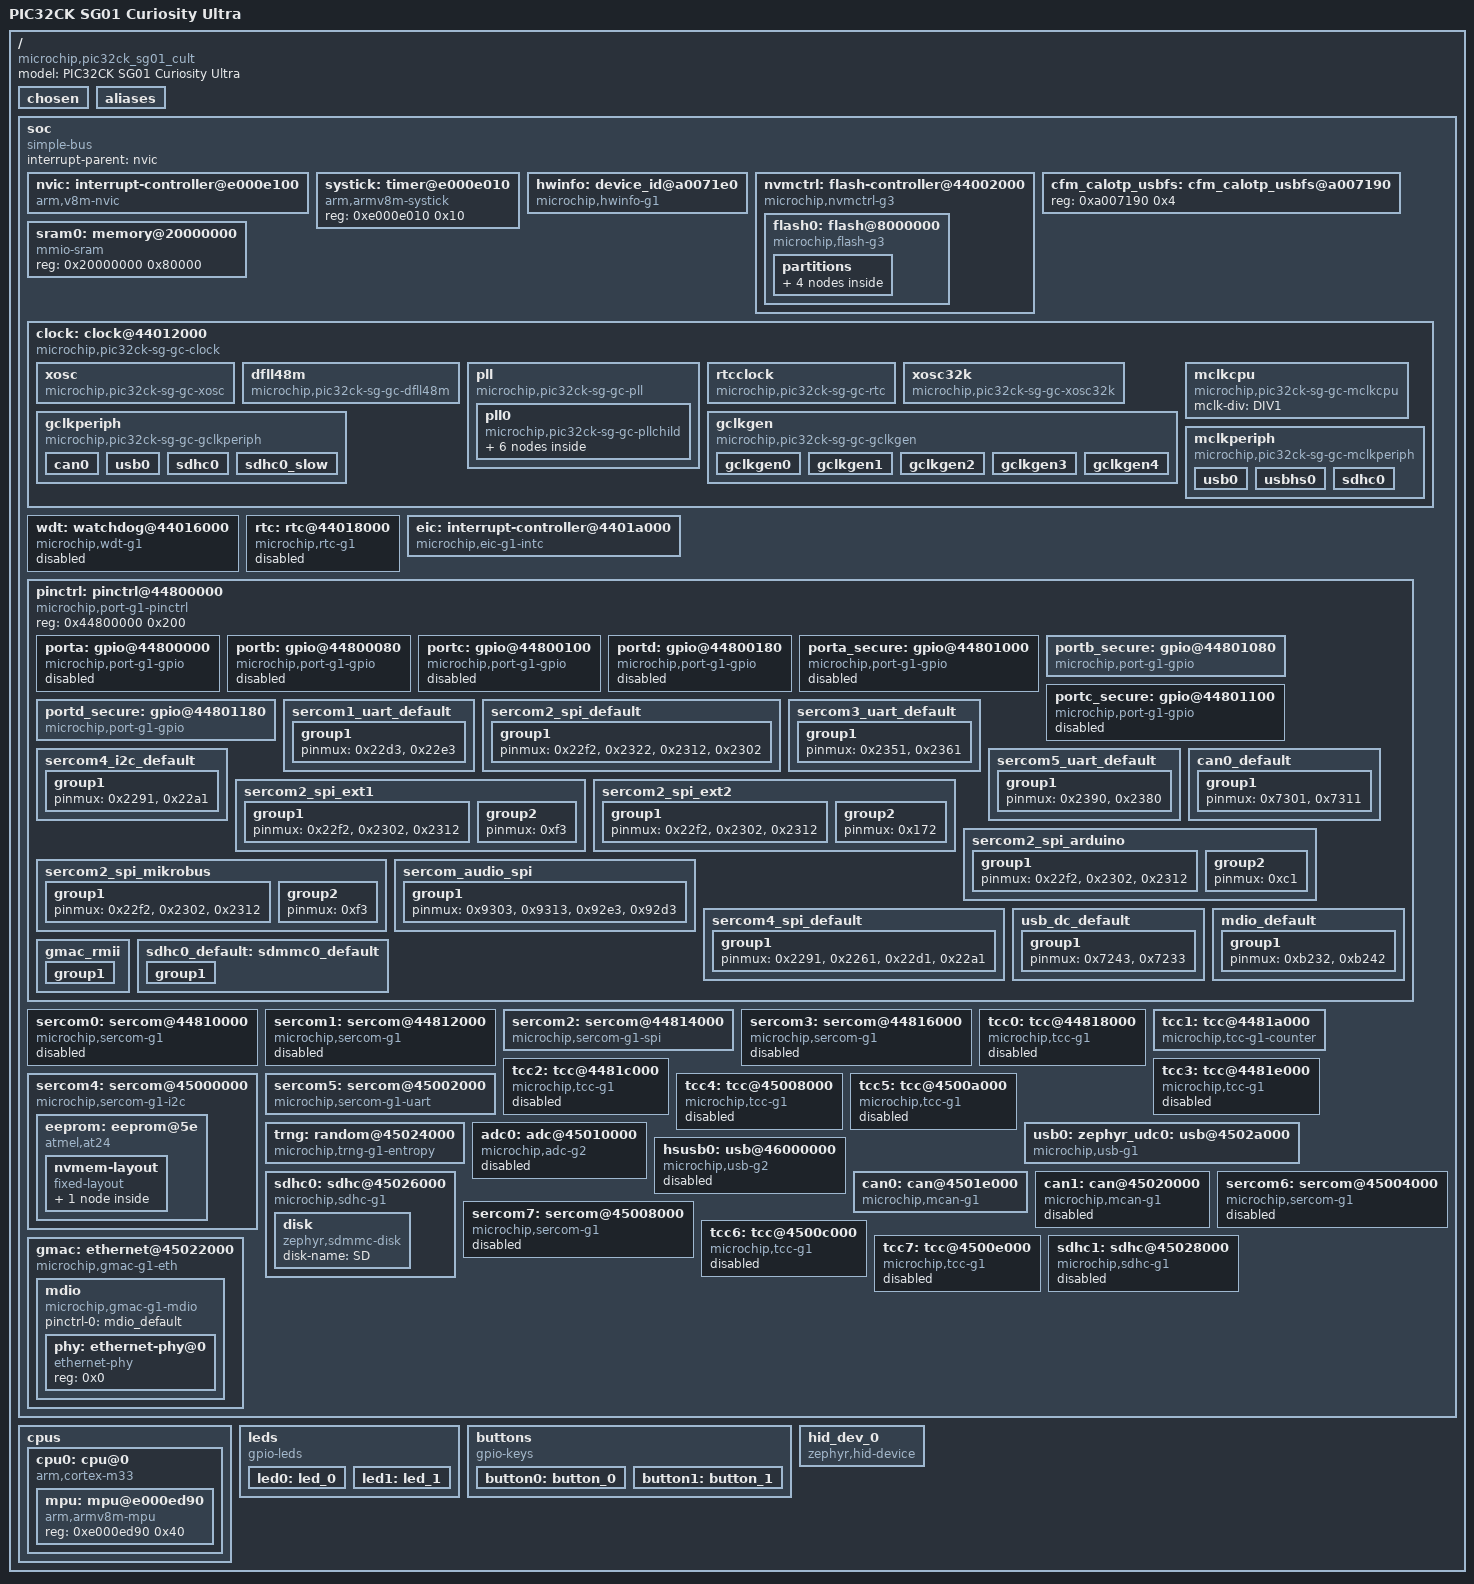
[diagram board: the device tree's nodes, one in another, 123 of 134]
/dts-v1/;

/* node '/' defined in zephyr\dts\common\skeleton.dtsi:9 */
/ {
	#address-cells = < 0x1 >;                   /* in zephyr\dts\common\skeleton.dtsi:10 */
	#size-cells = < 0x1 >;                      /* in zephyr\dts\common\skeleton.dtsi:11 */
	model = "PIC32CK SG01 Curiosity Ultra";     /* in zephyr\boards\microchip\pic32c\pic32ck_sg01_cult\pic32ck_sg01_cult.dts:14 */
	compatible = "microchip,pic32ck_sg01_cult"; /* in zephyr\boards\microchip\pic32c\pic32ck_sg01_cult\pic32ck_sg01_cult.dts:15 */

	/* node '/chosen' defined in zephyr\dts\common\skeleton.dtsi:13 */
	chosen {
		zephyr,sram = &sram0;                     /* in zephyr\boards\microchip\pic32c\pic32ck_sg01_cult\pic32ck_sg01_cult.dts:18 */
		zephyr,flash = &flash0;                   /* in zephyr\boards\microchip\pic32c\pic32ck_sg01_cult\pic32ck_sg01_cult.dts:19 */
		zephyr,flash-controller = &nvmctrl;       /* in zephyr\boards\microchip\pic32c\pic32ck_sg01_cult\pic32ck_sg01_cult.dts:20 */
		zephyr,code-partition = &slot0_partition; /* in zephyr\boards\microchip\pic32c\pic32ck_sg01_cult\pic32ck_sg01_cult.dts:21 */
		zephyr,console = &sercom5;                /* in zephyr\boards\microchip\pic32c\pic32ck_sg01_cult\pic32ck_sg01_cult.dts:22 */
		zephyr,shell-uart = &sercom5;             /* in zephyr\boards\microchip\pic32c\pic32ck_sg01_cult\pic32ck_sg01_cult.dts:23 */
		zephyr,canbus = &can0;                    /* in zephyr\boards\microchip\pic32c\pic32ck_sg01_cult\pic32ck_sg01_cult.dts:24 */
		zephyr,entropy = &trng;                   /* in zephyr\boards\microchip\pic32c\pic32ck_sg01_cult\pic32ck_sg01_cult.dts:25 */
		zephyr,sdhc = &sdhc0;                     /* in zephyr\boards\microchip\pic32c\pic32ck_sg01_cult\pic32ck_sg01_cult.dts:26 */
	};

	/* node '/aliases' defined in zephyr\dts\common\skeleton.dtsi:15 */
	aliases {
		watchdog0 = &wdt; /* in zephyr\dts\arm\microchip\pic32c\pic32ck_sg_gc\common\pic32ck_sg_gc.dtsi:13 */
		led0 = &led0;     /* in zephyr\boards\microchip\pic32c\pic32ck_sg01_cult\pic32ck_sg01_cult.dts:30 */
		led1 = &led1;     /* in zephyr\boards\microchip\pic32c\pic32ck_sg01_cult\pic32ck_sg01_cult.dts:31 */
		sw0 = &button0;   /* in zephyr\boards\microchip\pic32c\pic32ck_sg01_cult\pic32ck_sg01_cult.dts:32 */
		sw1 = &button1;   /* in zephyr\boards\microchip\pic32c\pic32ck_sg01_cult\pic32ck_sg01_cult.dts:33 */
		spi0 = &sercom2;  /* in zephyr\boards\microchip\pic32c\pic32ck_sg01_cult\pic32ck_sg01_cult.dts:34 */
		i2c0 = &sercom4;  /* in zephyr\boards\microchip\pic32c\pic32ck_sg01_cult\pic32ck_sg01_cult.dts:35 */
		sdhc0 = &sdhc0;   /* in zephyr\boards\microchip\pic32c\pic32ck_sg01_cult\pic32ck_sg01_cult.dts:36 */
	};

	/* node '/soc' defined in zephyr\dts\arm\armv8-m.dtsi:6 */
	soc {
		#address-cells = < 0x1 >;     /* in zephyr\dts\arm\armv8-m.dtsi:7 */
		#size-cells = < 0x1 >;        /* in zephyr\dts\arm\armv8-m.dtsi:8 */
		compatible = "simple-bus";    /* in zephyr\dts\arm\armv8-m.dtsi:9 */
		interrupt-parent = < &nvic >; /* in zephyr\dts\arm\armv8-m.dtsi:10 */
		ranges;                       /* in zephyr\dts\arm\armv8-m.dtsi:11 */

		/* node '/soc/interrupt-controller@e000e100' defined in zephyr\dts\arm\armv8-m.dtsi:13 */
		nvic: interrupt-controller@e000e100 {
			arm,num-irq-priority-bits = < 0x3 >; /* in zephyr\dts\arm\microchip\pic32c\pic32ck_sg_gc\common\pic32ck_sg_gc.dtsi:452 */
			#address-cells = < 0x1 >;            /* in zephyr\dts\arm\armv8-m.dtsi:14 */
			compatible = "arm,v8m-nvic";         /* in zephyr\dts\arm\armv8-m.dtsi:15 */
			reg = < 0xe000e100 0xc00 >;          /* in zephyr\dts\arm\armv8-m.dtsi:16 */
			interrupt-controller;                /* in zephyr\dts\arm\armv8-m.dtsi:17 */
			#interrupt-cells = < 0x2 >;          /* in zephyr\dts\arm\armv8-m.dtsi:18 */
			phandle = < 0x1 >;                   /* in zephyr\dts\arm\armv8-m.dtsi:10 */
		};

		/* node '/soc/timer@e000e010' defined in zephyr\dts\arm\armv8-m.dtsi:21 */
		systick: timer@e000e010 {
			compatible = "arm,armv8m-systick"; /* in zephyr\dts\arm\armv8-m.dtsi:22 */
			reg = < 0xe000e010 0x10 >;         /* in zephyr\dts\arm\armv8-m.dtsi:23 */
		};

		/* node '/soc/device_id@a0071e0' defined in zephyr\dts\arm\microchip\pic32c\pic32ck_sg_gc\common\pic32ck_sg_gc.dtsi:35 */
		hwinfo: device_id@a0071e0 {
			compatible = "microchip,hwinfo-g1"; /* in zephyr\dts\arm\microchip\pic32c\pic32ck_sg_gc\common\pic32ck_sg_gc.dtsi:36 */
			reg = < 0xa0071e0 0x4 >,
			      < 0xa0071e4 0x4 >,
			      < 0xa0071e8 0x4 >,
			      < 0xa0071ec 0x4 >;            /* in zephyr\dts\arm\microchip\pic32c\pic32ck_sg_gc\common\pic32ck_sg_gc.dtsi:37 */
		};

		/* node '/soc/flash-controller@44002000' defined in zephyr\dts\arm\microchip\pic32c\pic32ck_sg_gc\common\pic32ck_sg_gc.dtsi:43 */
		nvmctrl: flash-controller@44002000 {
			compatible = "microchip,nvmctrl-g3"; /* in zephyr\dts\arm\microchip\pic32c\pic32ck_sg_gc\common\pic32ck_sg_gc.dtsi:44 */
			reg = < 0x44002000 0x60 >,
			      < 0x44004000 0x7c >;           /* in zephyr\dts\arm\microchip\pic32c\pic32ck_sg_gc\common\pic32ck_sg_gc.dtsi:45 */
			reg-names = "fcr",
			            "fcw";                   /* in zephyr\dts\arm\microchip\pic32c\pic32ck_sg_gc\common\pic32ck_sg_gc.dtsi:46 */
			clock-parent = < &clock >;           /* in zephyr\dts\arm\microchip\pic32c\pic32ck_sg_gc\common\pic32ck_sg_gc.dtsi:47 */
			clocks = < &mclkperiph 0x24017f02 >,
			         < &mclkperiph 0x2410bf13 >,
			         < &mclkperiph 0x24013f01 >,
			         < &mclkperiph 0x24107f12 >; /* in zephyr\dts\arm\microchip\pic32c\pic32ck_sg_gc\common\pic32ck_sg_gc.dtsi:48 */
			clock-names = "mclk-fcw-ahb",
			              "mclk-fcw-apb",
			              "mclk-fcr-ahb",
			              "mclk-fcr-apb";        /* in zephyr\dts\arm\microchip\pic32c\pic32ck_sg_gc\common\pic32ck_sg_gc.dtsi:52 */
			interrupts = < 0x0 0x0 >,
			             < 0x1 0x0 >,
			             < 0x2 0x0 >;            /* in zephyr\dts\arm\microchip\pic32c\pic32ck_sg_gc\common\pic32ck_sg_gc.dtsi:54 */
			interrupt-names = "eccerr",
			                  "crcerr",
			                  "fcw";             /* in zephyr\dts\arm\microchip\pic32c\pic32ck_sg_gc\common\pic32ck_sg_gc.dtsi:55 */
			#address-cells = < 0x1 >;            /* in zephyr\dts\arm\microchip\pic32c\pic32ck_sg_gc\common\pic32ck_sg_gc.dtsi:56 */
			#size-cells = < 0x1 >;               /* in zephyr\dts\arm\microchip\pic32c\pic32ck_sg_gc\common\pic32ck_sg_gc.dtsi:57 */
			ranges;                              /* in zephyr\dts\arm\microchip\pic32c\pic32ck_sg_gc\common\pic32ck_sg_gc.dtsi:58 */

			/* node '/soc/flash-controller@44002000/flash@8000000' defined in zephyr\dts\arm\microchip\pic32c\pic32ck_sg_gc\common\pic32ck_sg_gc.dtsi:60 */
			flash0: flash@8000000 {
				compatible = "microchip,flash-g3",
				             "soc-nv-flash";                    /* in zephyr\dts\arm\microchip\pic32c\pic32ck_sg_gc\common\pic32ck_sg_gc.dtsi:61 */
				write-block-size = < 0x8 >;                     /* in zephyr\dts\arm\microchip\pic32c\pic32ck_sg_gc\common\pic32ck_sg_gc.dtsi:62 */
				write-block-size-quad-dw = < 0x20 >;            /* in zephyr\dts\arm\microchip\pic32c\pic32ck_sg_gc\common\pic32ck_sg_gc.dtsi:63 */
				write-block-size-row = < 0x400 >;               /* in zephyr\dts\arm\microchip\pic32c\pic32ck_sg_gc\common\pic32ck_sg_gc.dtsi:64 */
				erase-block-size = < 0x1000 >;                  /* in zephyr\dts\arm\microchip\pic32c\pic32ck_sg_gc\common\pic32ck_sg_gc.dtsi:65 */
				unimplemented-region = < 0x8020000 0xbffffff >; /* in zephyr\dts\arm\microchip\pic32c\pic32ck_sg_gc\common\pic32ck_sg_gc.dtsi:66 */
				reg = < 0x8000000 0x4200000 >;                  /* in zephyr\dts\arm\microchip\pic32c\pic32ck_sg_gc\common\pic32ck_2051_sg_gc.dtsi:13 */
				#address-cells = < 0x1 >;                       /* in zephyr\dts\arm\microchip\pic32c\pic32ck_sg_gc\common\pic32ck_2051_sg_gc.dtsi:15 */
				#size-cells = < 0x1 >;                          /* in zephyr\dts\arm\microchip\pic32c\pic32ck_sg_gc\common\pic32ck_2051_sg_gc.dtsi:16 */
				ranges = < 0x0 0x8000000 0x4200000 >;           /* in zephyr\dts\arm\microchip\pic32c\pic32ck_sg_gc\common\pic32ck_2051_sg_gc.dtsi:17 */

				/* node '/soc/flash-controller@44002000/flash@8000000/partitions' defined in zephyr\boards\microchip\pic32c\pic32ck_sg01_cult\pic32ck_sg01_cult.dts:71 */
				partitions {
					#address-cells = < 0x1 >; /* in zephyr\boards\microchip\pic32c\pic32ck_sg01_cult\pic32ck_sg01_cult.dts:72 */
					#size-cells = < 0x1 >;    /* in zephyr\boards\microchip\pic32c\pic32ck_sg01_cult\pic32ck_sg01_cult.dts:73 */
					ranges;                   /* in zephyr\boards\microchip\pic32c\pic32ck_sg01_cult\pic32ck_sg01_cult.dts:74 */

					/* node '/soc/flash-controller@44002000/flash@8000000/partitions/partition@0' defined in zephyr\boards\microchip\pic32c\pic32ck_sg01_cult\pic32ck_sg01_cult.dts:88 */
					boot_partition: partition@0 {
						compatible = "zephyr,mapped-partition"; /* in zephyr\boards\microchip\pic32c\pic32ck_sg01_cult\pic32ck_sg01_cult.dts:89 */
						label = "mcuboot";                      /* in zephyr\boards\microchip\pic32c\pic32ck_sg01_cult\pic32ck_sg01_cult.dts:90 */
						reg = < 0x0 0x20000 >;                  /* in zephyr\boards\microchip\pic32c\pic32ck_sg01_cult\pic32ck_sg01_cult.dts:91 */
					};

					/* node '/soc/flash-controller@44002000/flash@8000000/partitions/partition@4000000' defined in zephyr\boards\microchip\pic32c\pic32ck_sg01_cult\pic32ck_sg01_cult.dts:95 */
					slot0_partition: partition@4000000 {
						compatible = "zephyr,mapped-partition"; /* in zephyr\boards\microchip\pic32c\pic32ck_sg01_cult\pic32ck_sg01_cult.dts:96 */
						label = "image-0";                      /* in zephyr\boards\microchip\pic32c\pic32ck_sg01_cult\pic32ck_sg01_cult.dts:97 */
						reg = < 0x4000000 0xfc000 >;            /* in zephyr\boards\microchip\pic32c\pic32ck_sg01_cult\pic32ck_sg01_cult.dts:98 */
					};

					/* node '/soc/flash-controller@44002000/flash@8000000/partitions/partition@40fc000' defined in zephyr\boards\microchip\pic32c\pic32ck_sg01_cult\pic32ck_sg01_cult.dts:102 */
					slot1_partition: partition@40fc000 {
						compatible = "zephyr,mapped-partition"; /* in zephyr\boards\microchip\pic32c\pic32ck_sg01_cult\pic32ck_sg01_cult.dts:103 */
						label = "image-1";                      /* in zephyr\boards\microchip\pic32c\pic32ck_sg01_cult\pic32ck_sg01_cult.dts:104 */
						reg = < 0x40fc000 0xfc000 >;            /* in zephyr\boards\microchip\pic32c\pic32ck_sg01_cult\pic32ck_sg01_cult.dts:105 */
					};

					/* node '/soc/flash-controller@44002000/flash@8000000/partitions/partition@41f8000' defined in zephyr\boards\microchip\pic32c\pic32ck_sg01_cult\pic32ck_sg01_cult.dts:109 */
					storage_partition: partition@41f8000 {
						compatible = "zephyr,mapped-partition"; /* in zephyr\boards\microchip\pic32c\pic32ck_sg01_cult\pic32ck_sg01_cult.dts:110 */
						label = "storage";                      /* in zephyr\boards\microchip\pic32c\pic32ck_sg01_cult\pic32ck_sg01_cult.dts:111 */
						reg = < 0x41f8000 0x8000 >;             /* in zephyr\boards\microchip\pic32c\pic32ck_sg01_cult\pic32ck_sg01_cult.dts:112 */
					};
				};
			};
		};

		/* node '/soc/cfm_calotp_usbfs@a007190' defined in zephyr\dts\arm\microchip\pic32c\pic32ck_sg_gc\common\pic32ck_sg_gc.dtsi:71 */
		cfm_calotp_usbfs: cfm_calotp_usbfs@a007190 {
			reg = < 0xa007190 0x4 >; /* in zephyr\dts\arm\microchip\pic32c\pic32ck_sg_gc\common\pic32ck_sg_gc.dtsi:72 */
			phandle = < 0x9 >;       /* in zephyr\dts\arm\microchip\pic32c\pic32ck_sg_gc\common\pic32ck_sg_gc.dtsi:410 */
		};

		/* node '/soc/memory@20000000' defined in zephyr\dts\arm\microchip\pic32c\pic32ck_sg_gc\common\pic32ck_sg_gc.dtsi:75 */
		sram0: memory@20000000 {
			compatible = "mmio-sram";     /* in zephyr\dts\arm\microchip\pic32c\pic32ck_sg_gc\common\pic32ck_sg_gc.dtsi:76 */
			reg = < 0x20000000 0x80000 >; /* in zephyr\dts\arm\microchip\pic32c\pic32ck_sg_gc\common\pic32ck_2051_sg_gc.dtsi:23 */
		};

		/* node '/soc/clock@44012000' defined in zephyr\dts\arm\microchip\pic32c\pic32ck_sg_gc\common\pic32ck_sg_gc.dtsi:79 */
		clock: clock@44012000 {
			reg = < 0x44012000 0x2000 >,
			      < 0x4400c000 0x2000 >,
			      < 0x4400e000 0x2000 >,
			      < 0x44010000 0x2000 >,
			      < 0x44008000 0x2000 >;                  /* in zephyr\dts\arm\microchip\pic32c\pic32ck_sg_gc\common\pic32ck_sg_gc.dtsi:81 */
			reg-names = "mclk",
			            "oscctrl",
			            "osc32kctrl",
			            "gclk",
			            "supc";                           /* in zephyr\dts\arm\microchip\pic32c\pic32ck_sg_gc\common\pic32ck_sg_gc.dtsi:83 */
			interrupts = < 0x5 0x0 >,
			             < 0x5 0x0 >,
			             < 0x5 0x0 >,
			             < 0x6 0x0 >,
			             < 0x6 0x0 >,
			             < 0x6 0x0 >,
			             < 0x6 0x0 >,
			             < 0x6 0x0 >,
			             < 0x6 0x0 >,
			             < 0x7 0x0 >,
			             < 0x8 0x0 >,
			             < 0x8 0x0 >,
			             < 0x9 0x0 >;                     /* in zephyr\dts\arm\microchip\pic32c\pic32ck_sg_gc\common\pic32ck_sg_gc.dtsi:84 */
			interrupt-names = "xosc-fail",
			                  "xosc-crdy",
			                  "clk-fail",
			                  "dfll-rdy",
			                  "dfll-lock",
			                  "dfll-ovf",
			                  "dfll-unf",
			                  "dfll-rcs",
			                  "dfll-fail",
			                  "pll0-ckr",
			                  "xosc32k-rdy",
			                  "xosc32k-fail",
			                  "ckrdy";                    /* in zephyr\dts\arm\microchip\pic32c\pic32ck_sg_gc\common\pic32ck_sg_gc.dtsi:87 */
			compatible = "microchip,pic32ck-sg-gc-clock"; /* in zephyr\boards\microchip\pic32c\pic32ck_sg01_cult\pic32ck_sg01_cult.dts:122 */
			phandle = < 0x2 >;                            /* in zephyr\dts\arm\microchip\pic32c\pic32ck_sg_gc\common\pic32ck_sg_gc.dtsi:47 */

			/* node '/soc/clock@44012000/xosc' defined in zephyr\dts\arm\microchip\pic32c\pic32ck_sg_gc\common\pic32ck_sg_gc.dtsi:92 */
			xosc: xosc {
				compatible = "microchip,pic32ck-sg-gc-xosc";                 /* in zephyr\boards\microchip\pic32c\pic32ck_sg01_cult\pic32ck_sg01_cult.dts:125 */
				xosc-enable = < 0x1 >;                                       /* in zephyr\boards\microchip\pic32c\pic32ck_sg01_cult\pic32ck_sg01_cult.dts:126 */
				xosc-xtal-en = < 0x1 >;                                      /* in zephyr\boards\microchip\pic32c\pic32ck_sg01_cult\pic32ck_sg01_cult.dts:127 */
				xosc-auto-gain-control-loop-en = < 0x0 >;                    /* in zephyr\boards\microchip\pic32c\pic32ck_sg01_cult\pic32ck_sg01_cult.dts:128 */
				xosc-clock-switch-back-en = < 0x0 >;                         /* in zephyr\boards\microchip\pic32c\pic32ck_sg01_cult\pic32ck_sg01_cult.dts:129 */
				xosc-frequency = < 0xb71b00 >;                               /* in zephyr\boards\microchip\pic32c\pic32ck_sg01_cult\pic32ck_sg01_cult.dts:130 */
				xosc-on-demand-en = < 0x0 >;                                 /* in zephyr\boards\microchip\pic32c\pic32ck_sg01_cult\pic32ck_sg01_cult.dts:131 */
				xosc-startup-time = < 0x7a120 >;                             /* in zephyr\boards\microchip\pic32c\pic32ck_sg01_cult\pic32ck_sg01_cult.dts:132 */
				xosc-clock-failure-detection-en = < 0x0 >;                   /* in zephyr\boards\microchip\pic32c\pic32ck_sg01_cult\pic32ck_sg01_cult.dts:133 */
				xosc-safe-clock-frequency = < 0x30 >;                        /* in zephyr\boards\microchip\pic32c\pic32ck_sg01_cult\pic32ck_sg01_cult.dts:134 */
				xosc-usbhs-ref-clock-div = "usbhs-pll-ref-xosc-clock-div-1"; /* in zephyr\boards\microchip\pic32c\pic32ck_sg01_cult\pic32ck_sg01_cult.dts:135 */
			};

			/* node '/soc/clock@44012000/dfll48m' defined in zephyr\dts\arm\microchip\pic32c\pic32ck_sg_gc\common\pic32ck_sg_gc.dtsi:96 */
			dfll48m: dfll48m {
				compatible = "microchip,pic32ck-sg-gc-dfll48m"; /* in zephyr\boards\microchip\pic32c\pic32ck_sg01_cult\pic32ck_sg01_cult.dts:155 */
				dfll48m-src-gclk = "gclk1";                     /* in zephyr\boards\microchip\pic32c\pic32ck_sg01_cult\pic32ck_sg01_cult.dts:156 */
				dfll48m-enable = < 0x1 >;                       /* in zephyr\boards\microchip\pic32c\pic32ck_sg01_cult\pic32ck_sg01_cult.dts:157 */
				dfll48m-closed-loop-en = < 0x0 >;               /* in zephyr\boards\microchip\pic32c\pic32ck_sg01_cult\pic32ck_sg01_cult.dts:158 */
				dfll48m-on-demand-en = < 0x1 >;                 /* in zephyr\boards\microchip\pic32c\pic32ck_sg01_cult\pic32ck_sg01_cult.dts:159 */
				dfll48m-usb-clock-recovery-mode = < 0x1 >;      /* in zephyr\boards\microchip\pic32c\pic32ck_sg01_cult\pic32ck_sg01_cult.dts:160 */
				dfll48m-wait-lock-en = < 0x1 >;                 /* in zephyr\boards\microchip\pic32c\pic32ck_sg01_cult\pic32ck_sg01_cult.dts:161 */
				dfll48m-quick-lock-dis = < 0x1 >;               /* in zephyr\boards\microchip\pic32c\pic32ck_sg01_cult\pic32ck_sg01_cult.dts:162 */
				dfll48m-chill-cycle-dis = < 0x1 >;              /* in zephyr\boards\microchip\pic32c\pic32ck_sg01_cult\pic32ck_sg01_cult.dts:163 */
				dfll48m-lose-lock-en = < 0x1 >;                 /* in zephyr\boards\microchip\pic32c\pic32ck_sg01_cult\pic32ck_sg01_cult.dts:164 */
				dfll48m-stable-freq-en = < 0x1 >;               /* in zephyr\boards\microchip\pic32c\pic32ck_sg01_cult\pic32ck_sg01_cult.dts:165 */
				dfll48m-tune-max-step = < 0x1 >;                /* in zephyr\boards\microchip\pic32c\pic32ck_sg01_cult\pic32ck_sg01_cult.dts:166 */
				dfll48m-multiply-factor = < 0x1 >;              /* in zephyr\boards\microchip\pic32c\pic32ck_sg01_cult\pic32ck_sg01_cult.dts:167 */
			};

			/* node '/soc/clock@44012000/pll' defined in zephyr\dts\arm\microchip\pic32c\pic32ck_sg_gc\common\pic32ck_sg_gc.dtsi:100 */
			pll: pll {
				compatible = "microchip,pic32ck-sg-gc-pll"; /* in zephyr\boards\microchip\pic32c\pic32ck_sg01_cult\pic32ck_sg01_cult.dts:171 */

				/* node '/soc/clock@44012000/pll/pll0' defined in zephyr\dts\arm\microchip\pic32c\pic32ck_sg_gc\common\pic32ck_sg_gc.dtsi:103 */
				pll0: pll0 {
					compatible = "microchip,pic32ck-sg-gc-pllchild"; /* in zephyr\boards\microchip\pic32c\pic32ck_sg01_cult\pic32ck_sg01_cult.dts:174 */
					subsystem = < 0xbffc000 >;                       /* in zephyr\boards\microchip\pic32c\pic32ck_sg01_cult\pic32ck_sg01_cult.dts:176 */
					pll-enable = < 0x1 >;                            /* in zephyr\boards\microchip\pic32c\pic32ck_sg01_cult\pic32ck_sg01_cult.dts:177 */
					pll-on-demand-en = < 0x0 >;                      /* in zephyr\boards\microchip\pic32c\pic32ck_sg01_cult\pic32ck_sg01_cult.dts:178 */
					pll-bandwidth-sel = "bwsel-1";                   /* in zephyr\boards\microchip\pic32c\pic32ck_sg01_cult\pic32ck_sg01_cult.dts:179 */
					pll-src = "xosc";                                /* in zephyr\boards\microchip\pic32c\pic32ck_sg01_cult\pic32ck_sg01_cult.dts:180 */
					pll-ref-division-factor = < 0x3 >;               /* in zephyr\boards\microchip\pic32c\pic32ck_sg01_cult\pic32ck_sg01_cult.dts:181 */
					pll-feedback-divider-factor = < 0x12c >;         /* in zephyr\boards\microchip\pic32c\pic32ck_sg01_cult\pic32ck_sg01_cult.dts:182 */
					pll-freq-division-factor-int = < 0x0 >;          /* in zephyr\boards\microchip\pic32c\pic32ck_sg01_cult\pic32ck_sg01_cult.dts:183 */
					pll-freq-division-factor-rem = < 0x0 >;          /* in zephyr\boards\microchip\pic32c\pic32ck_sg01_cult\pic32ck_sg01_cult.dts:184 */

					/* node '/soc/clock@44012000/pll/pll0/pll0out0' defined in zephyr\boards\microchip\pic32c\pic32ck_sg01_cult\pic32ck_sg01_cult.dts:186 */
					pll0out0: pll0out0 {
						subsystem = < 0xfffff00 >;            /* in zephyr\boards\microchip\pic32c\pic32ck_sg01_cult\pic32ck_sg01_cult.dts:187 */
						pll-output-division-factor = < 0xa >; /* in zephyr\boards\microchip\pic32c\pic32ck_sg01_cult\pic32ck_sg01_cult.dts:188 */
						pll-output-en = < 0x1 >;              /* in zephyr\boards\microchip\pic32c\pic32ck_sg01_cult\pic32ck_sg01_cult.dts:189 */
					};

					/* node '/soc/clock@44012000/pll/pll0/pll0out1' defined in zephyr\boards\microchip\pic32c\pic32ck_sg01_cult\pic32ck_sg01_cult.dts:192 */
					pll0out1: pll0out1 {
						subsystem = < 0xfffff01 >;             /* in zephyr\boards\microchip\pic32c\pic32ck_sg01_cult\pic32ck_sg01_cult.dts:193 */
						pll-output-division-factor = < 0x19 >; /* in zephyr\boards\microchip\pic32c\pic32ck_sg01_cult\pic32ck_sg01_cult.dts:194 */
						pll-output-en = < 0x1 >;               /* in zephyr\boards\microchip\pic32c\pic32ck_sg01_cult\pic32ck_sg01_cult.dts:195 */
					};

					/* node '/soc/clock@44012000/pll/pll0/pll0out2' defined in zephyr\boards\microchip\pic32c\pic32ck_sg01_cult\pic32ck_sg01_cult.dts:198 */
					pll0out2: pll0out2 {
						subsystem = < 0xfffff02 >;            /* in zephyr\boards\microchip\pic32c\pic32ck_sg01_cult\pic32ck_sg01_cult.dts:199 */
						pll-output-division-factor = < 0xc >; /* in zephyr\boards\microchip\pic32c\pic32ck_sg01_cult\pic32ck_sg01_cult.dts:200 */
						pll-output-en = < 0x1 >;              /* in zephyr\boards\microchip\pic32c\pic32ck_sg01_cult\pic32ck_sg01_cult.dts:201 */
					};

					/* node '/soc/clock@44012000/pll/pll0/pll0out3' defined in zephyr\boards\microchip\pic32c\pic32ck_sg01_cult\pic32ck_sg01_cult.dts:204 */
					pll0out3: pll0out3 {
						subsystem = < 0xfffff03 >;            /* in zephyr\boards\microchip\pic32c\pic32ck_sg01_cult\pic32ck_sg01_cult.dts:205 */
						pll-output-division-factor = < 0x8 >; /* in zephyr\boards\microchip\pic32c\pic32ck_sg01_cult\pic32ck_sg01_cult.dts:206 */
						pll-output-en = < 0x0 >;              /* in zephyr\boards\microchip\pic32c\pic32ck_sg01_cult\pic32ck_sg01_cult.dts:207 */
					};

					/* node '/soc/clock@44012000/pll/pll0/pll0out4' defined in zephyr\boards\microchip\pic32c\pic32ck_sg01_cult\pic32ck_sg01_cult.dts:210 */
					pll0out4: pll0out4 {
						subsystem = < 0xfffff04 >;            /* in zephyr\boards\microchip\pic32c\pic32ck_sg01_cult\pic32ck_sg01_cult.dts:211 */
						pll-output-division-factor = < 0x8 >; /* in zephyr\boards\microchip\pic32c\pic32ck_sg01_cult\pic32ck_sg01_cult.dts:212 */
						pll-output-en = < 0x0 >;              /* in zephyr\boards\microchip\pic32c\pic32ck_sg01_cult\pic32ck_sg01_cult.dts:213 */
					};

					/* node '/soc/clock@44012000/pll/pll0/pll0out5' defined in zephyr\boards\microchip\pic32c\pic32ck_sg01_cult\pic32ck_sg01_cult.dts:216 */
					pll0out5: pll0out5 {
						subsystem = < 0xfffff05 >;            /* in zephyr\boards\microchip\pic32c\pic32ck_sg01_cult\pic32ck_sg01_cult.dts:217 */
						pll-output-division-factor = < 0x8 >; /* in zephyr\boards\microchip\pic32c\pic32ck_sg01_cult\pic32ck_sg01_cult.dts:218 */
						pll-output-en = < 0x0 >;              /* in zephyr\boards\microchip\pic32c\pic32ck_sg01_cult\pic32ck_sg01_cult.dts:219 */
					};
				};
			};

			/* node '/soc/clock@44012000/rtcclock' defined in zephyr\dts\arm\microchip\pic32c\pic32ck_sg_gc\common\pic32ck_sg_gc.dtsi:108 */
			rtcclock: rtcclock {
				compatible = "microchip,pic32ck-sg-gc-rtc"; /* in zephyr\dts\arm\microchip\pic32c\pic32ck_sg_gc\common\pic32ck_sg_gc.dtsi:109 */
				#clock-cells = < 0x1 >;                     /* in zephyr\dts\arm\microchip\pic32c\pic32ck_sg_gc\common\pic32ck_sg_gc.dtsi:110 */
				phandle = < 0x4 >;                          /* in zephyr\dts\arm\microchip\pic32c\pic32ck_sg_gc\common\pic32ck_sg_gc.dtsi:154 */
			};

			/* node '/soc/clock@44012000/xosc32k' defined in zephyr\dts\arm\microchip\pic32c\pic32ck_sg_gc\common\pic32ck_sg_gc.dtsi:113 */
			xosc32k: xosc32k {
				compatible = "microchip,pic32ck-sg-gc-xosc32k";      /* in zephyr\boards\microchip\pic32c\pic32ck_sg01_cult\pic32ck_sg01_cult.dts:139 */
				xosc32k-enable = < 0x1 >;                            /* in zephyr\boards\microchip\pic32c\pic32ck_sg01_cult\pic32ck_sg01_cult.dts:140 */
				xosc32k-xtal-en = < 0x1 >;                           /* in zephyr\boards\microchip\pic32c\pic32ck_sg01_cult\pic32ck_sg01_cult.dts:141 */
				xosc32k-frequency = < 0x8000 >;                      /* in zephyr\boards\microchip\pic32c\pic32ck_sg01_cult\pic32ck_sg01_cult.dts:142 */
				xosc32k-on-demand-en = < 0x0 >;                      /* in zephyr\boards\microchip\pic32c\pic32ck_sg01_cult\pic32ck_sg01_cult.dts:143 */
				xosc32k-control-gain-mode = "lower-gain-mode-value"; /* in zephyr\boards\microchip\pic32c\pic32ck_sg01_cult\pic32ck_sg01_cult.dts:144 */
				xosc32k-servo-loop-en = < 0x1 >;                     /* in zephyr\boards\microchip\pic32c\pic32ck_sg01_cult\pic32ck_sg01_cult.dts:145 */
				xosc32k-gain-boost = < 0x1 >;                        /* in zephyr\boards\microchip\pic32c\pic32ck_sg01_cult\pic32ck_sg01_cult.dts:146 */
				xosc32k-startup-time = < 0x3e8 >;                    /* in zephyr\boards\microchip\pic32c\pic32ck_sg01_cult\pic32ck_sg01_cult.dts:147 */
				xosc32k-rtc-clk-selection-en = < 0x1 >;              /* in zephyr\boards\microchip\pic32c\pic32ck_sg01_cult\pic32ck_sg01_cult.dts:148 */
				xosc32k-cfd-en = < 0x0 >;                            /* in zephyr\boards\microchip\pic32c\pic32ck_sg01_cult\pic32ck_sg01_cult.dts:149 */
				xosc32k-cfd-prescaler = < 0x0 >;                     /* in zephyr\boards\microchip\pic32c\pic32ck_sg01_cult\pic32ck_sg01_cult.dts:150 */
				xosc32k-cfd-switchback-en = < 0x0 >;                 /* in zephyr\boards\microchip\pic32c\pic32ck_sg01_cult\pic32ck_sg01_cult.dts:151 */
			};

			/* node '/soc/clock@44012000/gclkgen' defined in zephyr\dts\arm\microchip\pic32c\pic32ck_sg_gc\common\pic32ck_sg_gc.dtsi:117 */
			gclkgen: gclkgen {
				compatible = "microchip,pic32ck-sg-gc-gclkgen"; /* in zephyr\boards\microchip\pic32c\pic32ck_sg01_cult\pic32ck_sg01_cult.dts:225 */

				/* node '/soc/clock@44012000/gclkgen/gclkgen0' defined in zephyr\boards\microchip\pic32c\pic32ck_sg01_cult\pic32ck_sg01_cult.dts:227 */
				gclkgen0 {
					subsystem = < 0x1bffff00 >;               /* in zephyr\boards\microchip\pic32c\pic32ck_sg01_cult\pic32ck_sg01_cult.dts:228 */
					gclkgen-en = < 0x1 >;                     /* in zephyr\boards\microchip\pic32c\pic32ck_sg01_cult\pic32ck_sg01_cult.dts:229 */
					gclkgen-run-in-standby-en = < 0x0 >;      /* in zephyr\boards\microchip\pic32c\pic32ck_sg01_cult\pic32ck_sg01_cult.dts:230 */
					gclkgen-ext-input-frequency = < 0x0 >;    /* in zephyr\boards\microchip\pic32c\pic32ck_sg01_cult\pic32ck_sg01_cult.dts:231 */
					gclkgen-src = "pll0_0";                   /* in zephyr\boards\microchip\pic32c\pic32ck_sg01_cult\pic32ck_sg01_cult.dts:232 */
					gclkgen-output-off-val = "logic-level-0"; /* in zephyr\boards\microchip\pic32c\pic32ck_sg01_cult\pic32ck_sg01_cult.dts:233 */
					gclkgen-input-frequency = < 0x0 >;        /* in zephyr\boards\microchip\pic32c\pic32ck_sg01_cult\pic32ck_sg01_cult.dts:234 */
					gclkgen-div-select = "div-factor";        /* in zephyr\boards\microchip\pic32c\pic32ck_sg01_cult\pic32ck_sg01_cult.dts:235 */
					gclkgen-div-factor = < 0x1 >;             /* in zephyr\boards\microchip\pic32c\pic32ck_sg01_cult\pic32ck_sg01_cult.dts:236 */
					gclkgen-duty-50-50-en = < 0x0 >;          /* in zephyr\boards\microchip\pic32c\pic32ck_sg01_cult\pic32ck_sg01_cult.dts:237 */
					gclkgen-out-clock-signal = < 0x0 >;       /* in zephyr\boards\microchip\pic32c\pic32ck_sg01_cult\pic32ck_sg01_cult.dts:238 */
				};

				/* node '/soc/clock@44012000/gclkgen/gclkgen1' defined in zephyr\boards\microchip\pic32c\pic32ck_sg01_cult\pic32ck_sg01_cult.dts:241 */
				gclkgen1 {
					subsystem = < 0x1bffff01 >;               /* in zephyr\boards\microchip\pic32c\pic32ck_sg01_cult\pic32ck_sg01_cult.dts:242 */
					gclkgen-en = < 0x1 >;                     /* in zephyr\boards\microchip\pic32c\pic32ck_sg01_cult\pic32ck_sg01_cult.dts:243 */
					gclkgen-run-in-standby-en = < 0x0 >;      /* in zephyr\boards\microchip\pic32c\pic32ck_sg01_cult\pic32ck_sg01_cult.dts:244 */
					gclkgen-ext-input-frequency = < 0x0 >;    /* in zephyr\boards\microchip\pic32c\pic32ck_sg01_cult\pic32ck_sg01_cult.dts:245 */
					gclkgen-src = "pll0_0";                   /* in zephyr\boards\microchip\pic32c\pic32ck_sg01_cult\pic32ck_sg01_cult.dts:246 */
					gclkgen-output-off-val = "logic-level-0"; /* in zephyr\boards\microchip\pic32c\pic32ck_sg01_cult\pic32ck_sg01_cult.dts:247 */
					gclkgen-input-frequency = < 0x0 >;        /* in zephyr\boards\microchip\pic32c\pic32ck_sg01_cult\pic32ck_sg01_cult.dts:248 */
					gclkgen-div-select = "div-factor";        /* in zephyr\boards\microchip\pic32c\pic32ck_sg01_cult\pic32ck_sg01_cult.dts:249 */
					gclkgen-div-factor = < 0x2 >;             /* in zephyr\boards\microchip\pic32c\pic32ck_sg01_cult\pic32ck_sg01_cult.dts:250 */
					gclkgen-duty-50-50-en = < 0x0 >;          /* in zephyr\boards\microchip\pic32c\pic32ck_sg01_cult\pic32ck_sg01_cult.dts:251 */
					gclkgen-out-clock-signal = < 0x0 >;       /* in zephyr\boards\microchip\pic32c\pic32ck_sg01_cult\pic32ck_sg01_cult.dts:252 */
				};

				/* node '/soc/clock@44012000/gclkgen/gclkgen2' defined in zephyr\boards\microchip\pic32c\pic32ck_sg01_cult\pic32ck_sg01_cult.dts:256 */
				gclkgen2 {
					subsystem = < 0x1bffff02 >;               /* in zephyr\boards\microchip\pic32c\pic32ck_sg01_cult\pic32ck_sg01_cult.dts:257 */
					gclkgen-en = < 0x1 >;                     /* in zephyr\boards\microchip\pic32c\pic32ck_sg01_cult\pic32ck_sg01_cult.dts:258 */
					gclkgen-run-in-standby-en = < 0x0 >;      /* in zephyr\boards\microchip\pic32c\pic32ck_sg01_cult\pic32ck_sg01_cult.dts:259 */
					gclkgen-ext-input-frequency = < 0x0 >;    /* in zephyr\boards\microchip\pic32c\pic32ck_sg01_cult\pic32ck_sg01_cult.dts:260 */
					gclkgen-src = "pll0_1";                   /* in zephyr\boards\microchip\pic32c\pic32ck_sg01_cult\pic32ck_sg01_cult.dts:261 */
					gclkgen-output-off-val = "logic-level-0"; /* in zephyr\boards\microchip\pic32c\pic32ck_sg01_cult\pic32ck_sg01_cult.dts:262 */
					gclkgen-input-frequency = < 0x0 >;        /* in zephyr\boards\microchip\pic32c\pic32ck_sg01_cult\pic32ck_sg01_cult.dts:263 */
					gclkgen-div-select = "div-factor";        /* in zephyr\boards\microchip\pic32c\pic32ck_sg01_cult\pic32ck_sg01_cult.dts:264 */
					gclkgen-div-factor = < 0x1 >;             /* in zephyr\boards\microchip\pic32c\pic32ck_sg01_cult\pic32ck_sg01_cult.dts:265 */
					gclkgen-duty-50-50-en = < 0x0 >;          /* in zephyr\boards\microchip\pic32c\pic32ck_sg01_cult\pic32ck_sg01_cult.dts:266 */
					gclkgen-out-clock-signal = < 0x0 >;       /* in zephyr\boards\microchip\pic32c\pic32ck_sg01_cult\pic32ck_sg01_cult.dts:267 */
				};

				/* node '/soc/clock@44012000/gclkgen/gclkgen3' defined in zephyr\boards\microchip\pic32c\pic32ck_sg01_cult\pic32ck_sg01_cult.dts:271 */
				gclkgen3 {
					subsystem = < 0x1bffff03 >;               /* in zephyr\boards\microchip\pic32c\pic32ck_sg01_cult\pic32ck_sg01_cult.dts:272 */
					gclkgen-en = < 0x1 >;                     /* in zephyr\boards\microchip\pic32c\pic32ck_sg01_cult\pic32ck_sg01_cult.dts:273 */
					gclkgen-run-in-standby-en = < 0x0 >;      /* in zephyr\boards\microchip\pic32c\pic32ck_sg01_cult\pic32ck_sg01_cult.dts:274 */
					gclkgen-ext-input-frequency = < 0x0 >;    /* in zephyr\boards\microchip\pic32c\pic32ck_sg01_cult\pic32ck_sg01_cult.dts:275 */
					gclkgen-src = "pll0_2";                   /* in zephyr\boards\microchip\pic32c\pic32ck_sg01_cult\pic32ck_sg01_cult.dts:276 */
					gclkgen-output-off-val = "logic-level-0"; /* in zephyr\boards\microchip\pic32c\pic32ck_sg01_cult\pic32ck_sg01_cult.dts:277 */
					gclkgen-input-frequency = < 0x0 >;        /* in zephyr\boards\microchip\pic32c\pic32ck_sg01_cult\pic32ck_sg01_cult.dts:278 */
					gclkgen-div-select = "div-factor";        /* in zephyr\boards\microchip\pic32c\pic32ck_sg01_cult\pic32ck_sg01_cult.dts:279 */
					gclkgen-div-factor = < 0x1 >;             /* in zephyr\boards\microchip\pic32c\pic32ck_sg01_cult\pic32ck_sg01_cult.dts:280 */
					gclkgen-duty-50-50-en = < 0x0 >;          /* in zephyr\boards\microchip\pic32c\pic32ck_sg01_cult\pic32ck_sg01_cult.dts:281 */
					gclkgen-out-clock-signal = < 0x0 >;       /* in zephyr\boards\microchip\pic32c\pic32ck_sg01_cult\pic32ck_sg01_cult.dts:282 */
				};

				/* node '/soc/clock@44012000/gclkgen/gclkgen4' defined in zephyr\boards\microchip\pic32c\pic32ck_sg01_cult\pic32ck_sg01_cult.dts:286 */
				gclkgen4 {
					subsystem = < 0x1bffff04 >;               /* in zephyr\boards\microchip\pic32c\pic32ck_sg01_cult\pic32ck_sg01_cult.dts:287 */
					gclkgen-en = < 0x1 >;                     /* in zephyr\boards\microchip\pic32c\pic32ck_sg01_cult\pic32ck_sg01_cult.dts:288 */
					gclkgen-run-in-standby-en = < 0x0 >;      /* in zephyr\boards\microchip\pic32c\pic32ck_sg01_cult\pic32ck_sg01_cult.dts:289 */
					gclkgen-ext-input-frequency = < 0x0 >;    /* in zephyr\boards\microchip\pic32c\pic32ck_sg01_cult\pic32ck_sg01_cult.dts:290 */
					gclkgen-src = "xosc";                     /* in zephyr\boards\microchip\pic32c\pic32ck_sg01_cult\pic32ck_sg01_cult.dts:291 */
					gclkgen-output-off-val = "logic-level-0"; /* in zephyr\boards\microchip\pic32c\pic32ck_sg01_cult\pic32ck_sg01_cult.dts:292 */
					gclkgen-input-frequency = < 0x0 >;        /* in zephyr\boards\microchip\pic32c\pic32ck_sg01_cult\pic32ck_sg01_cult.dts:293 */
					gclkgen-div-select = "div-factor";        /* in zephyr\boards\microchip\pic32c\pic32ck_sg01_cult\pic32ck_sg01_cult.dts:294 */
					gclkgen-div-factor = < 0x1 >;             /* in zephyr\boards\microchip\pic32c\pic32ck_sg01_cult\pic32ck_sg01_cult.dts:295 */
					gclkgen-duty-50-50-en = < 0x0 >;          /* in zephyr\boards\microchip\pic32c\pic32ck_sg01_cult\pic32ck_sg01_cult.dts:296 */
					gclkgen-out-clock-signal = < 0x0 >;       /* in zephyr\boards\microchip\pic32c\pic32ck_sg01_cult\pic32ck_sg01_cult.dts:297 */
				};
			};

			/* node '/soc/clock@44012000/gclkperiph' defined in zephyr\dts\arm\microchip\pic32c\pic32ck_sg_gc\common\pic32ck_sg_gc.dtsi:121 */
			gclkperiph: gclkperiph {
				compatible = "microchip,pic32ck-sg-gc-gclkperiph"; /* in zephyr\boards\microchip\pic32c\pic32ck_sg01_cult\pic32ck_sg01_cult.dts:302 */
				#clock-cells = < 0x1 >;                            /* in zephyr\boards\microchip\pic32c\pic32ck_sg01_cult\pic32ck_sg01_cult.dts:303 */
				phandle = < 0x5 >;                                 /* in zephyr\dts\arm\microchip\pic32c\pic32ck_sg_gc\common\pic32ck_sg_gc.dtsi:174 */

				/* node '/soc/clock@44012000/gclkperiph/can0' defined in zephyr\boards\microchip\pic32c\pic32ck_sg01_cult\pic32ck_sg01_cult.dts:305 */
				can0 {
					subsystem = < 0x1fffe730 >; /* in zephyr\boards\microchip\pic32c\pic32ck_sg01_cult\pic32ck_sg01_cult.dts:306 */
					gclkperiph-src = "gclk0";   /* in zephyr\boards\microchip\pic32c\pic32ck_sg01_cult\pic32ck_sg01_cult.dts:307 */
					gclkperiph-en = < 0x1 >;    /* in zephyr\boards\microchip\pic32c\pic32ck_sg01_cult\pic32ck_sg01_cult.dts:308 */
				};

				/* node '/soc/clock@44012000/gclkperiph/usb0' defined in zephyr\boards\microchip\pic32c\pic32ck_sg01_cult\pic32ck_sg01_cult.dts:311 */
				usb0 {
					subsystem = < 0x1fffee37 >; /* in zephyr\boards\microchip\pic32c\pic32ck_sg01_cult\pic32ck_sg01_cult.dts:312 */
					gclkperiph-src = "gclk2";   /* in zephyr\boards\microchip\pic32c\pic32ck_sg01_cult\pic32ck_sg01_cult.dts:313 */
					gclkperiph-en = < 0x1 >;    /* in zephyr\boards\microchip\pic32c\pic32ck_sg01_cult\pic32ck_sg01_cult.dts:314 */
				};

				/* node '/soc/clock@44012000/gclkperiph/sdhc0' defined in zephyr\boards\microchip\pic32c\pic32ck_sg01_cult\pic32ck_sg01_cult.dts:317 */
				sdhc0 {
					subsystem = < 0x1fffec35 >; /* in zephyr\boards\microchip\pic32c\pic32ck_sg01_cult\pic32ck_sg01_cult.dts:318 */
					gclkperiph-src = "gclk3";   /* in zephyr\boards\microchip\pic32c\pic32ck_sg01_cult\pic32ck_sg01_cult.dts:319 */
					gclkperiph-en = < 0x1 >;    /* in zephyr\boards\microchip\pic32c\pic32ck_sg01_cult\pic32ck_sg01_cult.dts:320 */
				};

				/* node '/soc/clock@44012000/gclkperiph/sdhc0_slow' defined in zephyr\boards\microchip\pic32c\pic32ck_sg01_cult\pic32ck_sg01_cult.dts:323 */
				sdhc0_slow {
					subsystem = < 0x1fffd210 >; /* in zephyr\boards\microchip\pic32c\pic32ck_sg01_cult\pic32ck_sg01_cult.dts:324 */
					gclkperiph-src = "gclk4";   /* in zephyr\boards\microchip\pic32c\pic32ck_sg01_cult\pic32ck_sg01_cult.dts:325 */
					gclkperiph-en = < 0x1 >;    /* in zephyr\boards\microchip\pic32c\pic32ck_sg01_cult\pic32ck_sg01_cult.dts:326 */
				};
			};

			/* node '/soc/clock@44012000/mclkcpu' defined in zephyr\dts\arm\microchip\pic32c\pic32ck_sg_gc\common\pic32ck_sg_gc.dtsi:126 */
			mclkcpu: mclkcpu {
				compatible = "microchip,pic32ck-sg-gc-mclkcpu"; /* in zephyr\boards\microchip\pic32c\pic32ck_sg01_cult\pic32ck_sg01_cult.dts:331 */
				mclk-div = "DIV1";                              /* in zephyr\boards\microchip\pic32c\pic32ck_sg01_cult\pic32ck_sg01_cult.dts:332 */
			};

			/* node '/soc/clock@44012000/mclkperiph' defined in zephyr\dts\arm\microchip\pic32c\pic32ck_sg_gc\common\pic32ck_sg_gc.dtsi:130 */
			mclkperiph: mclkperiph {
				compatible = "microchip,pic32ck-sg-gc-mclkperiph"; /* in zephyr\boards\microchip\pic32c\pic32ck_sg01_cult\pic32ck_sg01_cult.dts:336 */
				#clock-cells = < 0x1 >;                            /* in zephyr\boards\microchip\pic32c\pic32ck_sg01_cult\pic32ck_sg01_cult.dts:337 */
				phandle = < 0x3 >;                                 /* in zephyr\dts\arm\microchip\pic32c\pic32ck_sg_gc\common\pic32ck_sg_gc.dtsi:48 */

				/* node '/soc/clock@44012000/mclkperiph/usb0' defined in zephyr\boards\microchip\pic32c\pic32ck_sg01_cult\pic32ck_sg01_cult.dts:339 */
				usb0 {
					subsystem = < 0x24347f3e >; /* in zephyr\boards\microchip\pic32c\pic32ck_sg01_cult\pic32ck_sg01_cult.dts:340 */
					mclk-en = < 0x1 >;          /* in zephyr\boards\microchip\pic32c\pic32ck_sg01_cult\pic32ck_sg01_cult.dts:341 */
				};

				/* node '/soc/clock@44012000/mclkperiph/usbhs0' defined in zephyr\boards\microchip\pic32c\pic32ck_sg01_cult\pic32ck_sg01_cult.dts:344 */
				usbhs0 {
					subsystem = < 0x24053f0e >; /* in zephyr\boards\microchip\pic32c\pic32ck_sg01_cult\pic32ck_sg01_cult.dts:345 */
					mclk-en = < 0x1 >;          /* in zephyr\boards\microchip\pic32c\pic32ck_sg01_cult\pic32ck_sg01_cult.dts:346 */
				};

				/* node '/soc/clock@44012000/mclkperiph/sdhc0' defined in zephyr\boards\microchip\pic32c\pic32ck_sg01_cult\pic32ck_sg01_cult.dts:349 */
				sdhc0 {
					subsystem = < 0x24047f0b >; /* in zephyr\boards\microchip\pic32c\pic32ck_sg01_cult\pic32ck_sg01_cult.dts:350 */
					mclk-en = < 0x1 >;          /* in zephyr\boards\microchip\pic32c\pic32ck_sg01_cult\pic32ck_sg01_cult.dts:351 */
				};
			};
		};

		/* node '/soc/watchdog@44016000' defined in zephyr\dts\arm\microchip\pic32c\pic32ck_sg_gc\common\pic32ck_sg_gc.dtsi:136 */
		wdt: watchdog@44016000 {
			compatible = "microchip,wdt-g1";         /* in zephyr\dts\arm\microchip\pic32c\pic32ck_sg_gc\common\pic32ck_sg_gc.dtsi:137 */
			reg = < 0x44016000 0xd >;                /* in zephyr\dts\arm\microchip\pic32c\pic32ck_sg_gc\common\pic32ck_sg_gc.dtsi:138 */
			interrupts = < 0xb 0x0 >;                /* in zephyr\dts\arm\microchip\pic32c\pic32ck_sg_gc\common\pic32ck_sg_gc.dtsi:139 */
			interrupt-names = "wdt-ew";              /* in zephyr\dts\arm\microchip\pic32c\pic32ck_sg_gc\common\pic32ck_sg_gc.dtsi:140 */
			clocks = < &mclkperiph 0x2412ff18 >;     /* in zephyr\dts\arm\microchip\pic32c\pic32ck_sg_gc\common\pic32ck_sg_gc.dtsi:141 */
			clock-names = "mclk";                    /* in zephyr\dts\arm\microchip\pic32c\pic32ck_sg_gc\common\pic32ck_sg_gc.dtsi:142 */
			max-installable-timeout-count = < 0x1 >; /* in zephyr\dts\arm\microchip\pic32c\pic32ck_sg_gc\common\pic32ck_sg_gc.dtsi:143 */
			max-timeout-window = < 0x4000 >;         /* in zephyr\dts\arm\microchip\pic32c\pic32ck_sg_gc\common\pic32ck_sg_gc.dtsi:144 */
			max-timeout-window-mode = < 0x8000 >;    /* in zephyr\dts\arm\microchip\pic32c\pic32ck_sg_gc\common\pic32ck_sg_gc.dtsi:145 */
			min-window-limit = < 0x8 >;              /* in zephyr\dts\arm\microchip\pic32c\pic32ck_sg_gc\common\pic32ck_sg_gc.dtsi:146 */
			status = "disabled";                     /* in zephyr\dts\arm\microchip\pic32c\pic32ck_sg_gc\common\pic32ck_sg_gc.dtsi:147 */
		};

		/* node '/soc/rtc@44018000' defined in zephyr\dts\arm\microchip\pic32c\pic32ck_sg_gc\common\pic32ck_sg_gc.dtsi:150 */
		rtc: rtc@44018000 {
			compatible = "microchip,rtc-g1";     /* in zephyr\dts\arm\microchip\pic32c\pic32ck_sg_gc\common\pic32ck_sg_gc.dtsi:151 */
			reg = < 0x44018000 0x70 >;           /* in zephyr\dts\arm\microchip\pic32c\pic32ck_sg_gc\common\pic32ck_sg_gc.dtsi:152 */
			interrupts = < 0xc 0x0 >;            /* in zephyr\dts\arm\microchip\pic32c\pic32ck_sg_gc\common\pic32ck_sg_gc.dtsi:153 */
			clocks = < &mclkperiph 0x24133f19 >,
			         < &rtcclock 0x13ffff00 >;   /* in zephyr\dts\arm\microchip\pic32c\pic32ck_sg_gc\common\pic32ck_sg_gc.dtsi:154 */
			clock-names = "mclk",
			              "rtcclk";              /* in zephyr\dts\arm\microchip\pic32c\pic32ck_sg_gc\common\pic32ck_sg_gc.dtsi:156 */
			prescaler = < 0x1 >;                 /* in zephyr\dts\arm\microchip\pic32c\pic32ck_sg_gc\common\pic32ck_sg_gc.dtsi:157 */
			alarms-count = < 0x2 >;              /* in zephyr\dts\arm\microchip\pic32c\pic32ck_sg_gc\common\pic32ck_sg_gc.dtsi:158 */
			cal-constant = < 0x100000 >;         /* in zephyr\dts\arm\microchip\pic32c\pic32ck_sg_gc\common\pic32ck_sg_gc.dtsi:159 */
			status = "disabled";                 /* in zephyr\dts\arm\microchip\pic32c\pic32ck_sg_gc\common\pic32ck_sg_gc.dtsi:160 */
		};

		/* node '/soc/interrupt-controller@4401a000' defined in zephyr\dts\arm\microchip\pic32c\pic32ck_sg_gc\common\pic32ck_sg_gc.dtsi:163 */
		eic: interrupt-controller@4401a000 {
			compatible = "microchip,eic-g1-intc";    /* in zephyr\dts\arm\microchip\pic32c\pic32ck_sg_gc\common\pic32ck_sg_gc.dtsi:164 */
			reg = < 0x4401a000 0x2000 >;             /* in zephyr\dts\arm\microchip\pic32c\pic32ck_sg_gc\common\pic32ck_sg_gc.dtsi:165 */
			interrupts = < 0xd 0x0 >,
			             < 0xe 0x0 >,
			             < 0xf 0x0 >,
			             < 0x10 0x0 >,
			             < 0x11 0x0 >,
			             < 0x12 0x0 >,
			             < 0x13 0x0 >,
			             < 0x14 0x0 >,
			             < 0x15 0x0 >,
			             < 0x16 0x0 >,
			             < 0x17 0x0 >,
			             < 0x18 0x0 >,
			             < 0x19 0x0 >,
			             < 0x1a 0x0 >,
			             < 0x1b 0x0 >,
			             < 0x1c 0x0 >;               /* in zephyr\dts\arm\microchip\pic32c\pic32ck_sg_gc\common\pic32ck_sg_gc.dtsi:166 */
			interrupt-names = "extint-0",
			                  "extint-1",
			                  "extint-2",
			                  "extint-3",
			                  "extint-4",
			                  "extint-5",
			                  "extint-6",
			                  "extint-7",
			                  "extint-8",
			                  "extint-9",
			                  "extint-10",
			                  "extint-11",
			                  "extint-12",
			                  "extint-13",
			                  "extint-14",
			                  "extint-15";           /* in zephyr\dts\arm\microchip\pic32c\pic32ck_sg_gc\common\pic32ck_sg_gc.dtsi:170 */
			clocks = < &mclkperiph 0x24137f1a >,
			         < &gclkperiph 0x1fffc503 >;     /* in zephyr\dts\arm\microchip\pic32c\pic32ck_sg_gc\common\pic32ck_sg_gc.dtsi:174 */
			clock-names = "mclk",
			              "gclk";                    /* in zephyr\dts\arm\microchip\pic32c\pic32ck_sg_gc\common\pic32ck_sg_gc.dtsi:176 */
			low-power-mode;                          /* in zephyr\dts\arm\microchip\pic32c\pic32ck_sg_gc\common\pic32ck_sg_gc.dtsi:177 */
			porta-unsupported-pins = < 0xe0080000 >; /* in zephyr\dts\arm\microchip\pic32c\pic32ck_sg_gc\common\pic32ck_sg_gc.dtsi:182 */
			portc-unsupported-pins = < 0x100 >;      /* in zephyr\dts\arm\microchip\pic32c\pic32ck_sg_gc\common\pic32ck_sg_gc.dtsi:183 */
			portd-supported-pins = < 0x3f7ffe >;     /* in zephyr\dts\arm\microchip\pic32c\pic32ck_sg_gc\common\pic32ck_sg_gc.dtsi:186 */
			porta-special-pins-1 = < 0x1 0xe >;      /* in zephyr\dts\arm\microchip\pic32c\pic32ck_sg_gc\common\pic32ck_sg_gc.dtsi:188 */
		};

		/* node '/soc/pinctrl@44800000' defined in zephyr\dts\arm\microchip\pic32c\pic32ck_sg_gc\common\pic32ck_sg_gc.dtsi:191 */
		pinctrl: pinctrl@44800000 {
			compatible = "microchip,port-g1-pinctrl"; /* in zephyr\dts\arm\microchip\pic32c\pic32ck_sg_gc\common\pic32ck_sg_gc.dtsi:192 */
			#address-cells = < 0x1 >;                 /* in zephyr\dts\arm\microchip\pic32c\pic32ck_sg_gc\common\pic32ck_sg_gc.dtsi:193 */
			#size-cells = < 0x1 >;                    /* in zephyr\dts\arm\microchip\pic32c\pic32ck_sg_gc\common\pic32ck_sg_gc.dtsi:194 */
			reg = < 0x44800000 0x200 >;               /* in zephyr\dts\arm\microchip\pic32c\pic32ck_sg_gc\common\pic32ck_sg_gc.dtsi:195 */
			ranges = < 0x44800000 0x44800000 0x200 >; /* in zephyr\dts\arm\microchip\pic32c\pic32ck_sg_gc\common\pic32ck_sg_gc.dtsi:196 */

			/* node '/soc/pinctrl@44800000/gpio@44800000' defined in zephyr\dts\arm\microchip\pic32c\pic32ck_sg_gc\common\pic32ck_sg_gc.dtsi:198 */
			porta: gpio@44800000 {
				compatible = "microchip,port-g1-gpio"; /* in zephyr\dts\arm\microchip\pic32c\pic32ck_sg_gc\common\pic32ck_sg_gc.dtsi:199 */
				reg = < 0x44800000 0x80 >;             /* in zephyr\dts\arm\microchip\pic32c\pic32ck_sg_gc\common\pic32ck_sg_gc.dtsi:200 */
				gpio-controller;                       /* in zephyr\dts\arm\microchip\pic32c\pic32ck_sg_gc\common\pic32ck_sg_gc.dtsi:201 */
				#gpio-cells = < 0x2 >;                 /* in zephyr\dts\arm\microchip\pic32c\pic32ck_sg_gc\common\pic32ck_sg_gc.dtsi:202 */
				#microchip,pin-cells = < 0x2 >;        /* in zephyr\dts\arm\microchip\pic32c\pic32ck_sg_gc\common\pic32ck_sg_gc.dtsi:203 */
				status = "disabled";                   /* in zephyr\dts\arm\microchip\pic32c\pic32ck_sg_gc\common\pic32ck_sg_gc.dtsi:204 */
			};

			/* node '/soc/pinctrl@44800000/gpio@44800080' defined in zephyr\dts\arm\microchip\pic32c\pic32ck_sg_gc\common\pic32ck_sg_gc.dtsi:207 */
			portb: gpio@44800080 {
				compatible = "microchip,port-g1-gpio"; /* in zephyr\dts\arm\microchip\pic32c\pic32ck_sg_gc\common\pic32ck_sg_gc.dtsi:208 */
				reg = < 0x44800080 0x80 >;             /* in zephyr\dts\arm\microchip\pic32c\pic32ck_sg_gc\common\pic32ck_sg_gc.dtsi:209 */
				gpio-controller;                       /* in zephyr\dts\arm\microchip\pic32c\pic32ck_sg_gc\common\pic32ck_sg_gc.dtsi:210 */
				#gpio-cells = < 0x2 >;                 /* in zephyr\dts\arm\microchip\pic32c\pic32ck_sg_gc\common\pic32ck_sg_gc.dtsi:211 */
				#microchip,pin-cells = < 0x2 >;        /* in zephyr\dts\arm\microchip\pic32c\pic32ck_sg_gc\common\pic32ck_sg_gc.dtsi:212 */
				status = "disabled";                   /* in zephyr\dts\arm\microchip\pic32c\pic32ck_sg_gc\common\pic32ck_sg_gc.dtsi:213 */
			};

			/* node '/soc/pinctrl@44800000/gpio@44800100' defined in zephyr\dts\arm\microchip\pic32c\pic32ck_sg_gc\common\pic32ck_sg_gc.dtsi:216 */
			portc: gpio@44800100 {
				compatible = "microchip,port-g1-gpio"; /* in zephyr\dts\arm\microchip\pic32c\pic32ck_sg_gc\common\pic32ck_sg_gc.dtsi:217 */
				reg = < 0x44800100 0x80 >;             /* in zephyr\dts\arm\microchip\pic32c\pic32ck_sg_gc\common\pic32ck_sg_gc.dtsi:218 */
				gpio-controller;                       /* in zephyr\dts\arm\microchip\pic32c\pic32ck_sg_gc\common\pic32ck_sg_gc.dtsi:219 */
				#gpio-cells = < 0x2 >;                 /* in zephyr\dts\arm\microchip\pic32c\pic32ck_sg_gc\common\pic32ck_sg_gc.dtsi:220 */
				#microchip,pin-cells = < 0x2 >;        /* in zephyr\dts\arm\microchip\pic32c\pic32ck_sg_gc\common\pic32ck_sg_gc.dtsi:221 */
				status = "disabled";                   /* in zephyr\dts\arm\microchip\pic32c\pic32ck_sg_gc\common\pic32ck_sg_gc.dtsi:222 */
			};

			/* node '/soc/pinctrl@44800000/gpio@44800180' defined in zephyr\dts\arm\microchip\pic32c\pic32ck_sg_gc\common\pic32ck_sg_gc.dtsi:225 */
			portd: gpio@44800180 {
				compatible = "microchip,port-g1-gpio"; /* in zephyr\dts\arm\microchip\pic32c\pic32ck_sg_gc\common\pic32ck_sg_gc.dtsi:226 */
				reg = < 0x44800180 0x80 >;             /* in zephyr\dts\arm\microchip\pic32c\pic32ck_sg_gc\common\pic32ck_sg_gc.dtsi:227 */
				gpio-controller;                       /* in zephyr\dts\arm\microchip\pic32c\pic32ck_sg_gc\common\pic32ck_sg_gc.dtsi:228 */
				#gpio-cells = < 0x2 >;                 /* in zephyr\dts\arm\microchip\pic32c\pic32ck_sg_gc\common\pic32ck_sg_gc.dtsi:229 */
				#microchip,pin-cells = < 0x2 >;        /* in zephyr\dts\arm\microchip\pic32c\pic32ck_sg_gc\common\pic32ck_sg_gc.dtsi:230 */
				status = "disabled";                   /* in zephyr\dts\arm\microchip\pic32c\pic32ck_sg_gc\common\pic32ck_sg_gc.dtsi:231 */
			};

			/* node '/soc/pinctrl@44800000/gpio@44801000' defined in zephyr\dts\arm\microchip\pic32c\pic32ck_sg_gc\common\pic32ck_sg.dtsi:8 */
			porta_secure: gpio@44801000 {
				compatible = "microchip,port-g1-gpio"; /* in zephyr\dts\arm\microchip\pic32c\pic32ck_sg_gc\common\pic32ck_sg.dtsi:9 */
				reg = < 0x44801000 0x80 >;             /* in zephyr\dts\arm\microchip\pic32c\pic32ck_sg_gc\common\pic32ck_sg.dtsi:10 */
				gpio-controller;                       /* in zephyr\dts\arm\microchip\pic32c\pic32ck_sg_gc\common\pic32ck_sg.dtsi:11 */
				#gpio-cells = < 0x2 >;                 /* in zephyr\dts\arm\microchip\pic32c\pic32ck_sg_gc\common\pic32ck_sg.dtsi:12 */
				#microchip,pin-cells = < 0x2 >;        /* in zephyr\dts\arm\microchip\pic32c\pic32ck_sg_gc\common\pic32ck_sg.dtsi:13 */
				status = "disabled";                   /* in zephyr\dts\arm\microchip\pic32c\pic32ck_sg_gc\common\pic32ck_sg.dtsi:14 */
			};

			/* node '/soc/pinctrl@44800000/gpio@44801080' defined in zephyr\dts\arm\microchip\pic32c\pic32ck_sg_gc\common\pic32ck_sg.dtsi:17 */
			portb_secure: gpio@44801080 {
				compatible = "microchip,port-g1-gpio"; /* in zephyr\dts\arm\microchip\pic32c\pic32ck_sg_gc\common\pic32ck_sg.dtsi:18 */
				reg = < 0x44801080 0x80 >;             /* in zephyr\dts\arm\microchip\pic32c\pic32ck_sg_gc\common\pic32ck_sg.dtsi:19 */
				gpio-controller;                       /* in zephyr\dts\arm\microchip\pic32c\pic32ck_sg_gc\common\pic32ck_sg.dtsi:20 */
				#gpio-cells = < 0x2 >;                 /* in zephyr\dts\arm\microchip\pic32c\pic32ck_sg_gc\common\pic32ck_sg.dtsi:21 */
				#microchip,pin-cells = < 0x2 >;        /* in zephyr\dts\arm\microchip\pic32c\pic32ck_sg_gc\common\pic32ck_sg.dtsi:22 */
				status = "okay";                       /* in zephyr\boards\microchip\pic32c\pic32ck_sg01_cult\pic32ck_sg01_cult.dts:364 */
				phandle = < 0x12 >;                    /* in zephyr\boards\microchip\pic32c\pic32ck_sg01_cult\pic32ck_sg01_cult.dts:48 */
			};

			/* node '/soc/pinctrl@44800000/gpio@44801100' defined in zephyr\dts\arm\microchip\pic32c\pic32ck_sg_gc\common\pic32ck_sg.dtsi:26 */
			portc_secure: gpio@44801100 {
				compatible = "microchip,port-g1-gpio"; /* in zephyr\dts\arm\microchip\pic32c\pic32ck_sg_gc\common\pic32ck_sg.dtsi:27 */
				reg = < 0x44801100 0x80 >;             /* in zephyr\dts\arm\microchip\pic32c\pic32ck_sg_gc\common\pic32ck_sg.dtsi:28 */
				gpio-controller;                       /* in zephyr\dts\arm\microchip\pic32c\pic32ck_sg_gc\common\pic32ck_sg.dtsi:29 */
				#gpio-cells = < 0x2 >;                 /* in zephyr\dts\arm\microchip\pic32c\pic32ck_sg_gc\common\pic32ck_sg.dtsi:30 */
				#microchip,pin-cells = < 0x2 >;        /* in zephyr\dts\arm\microchip\pic32c\pic32ck_sg_gc\common\pic32ck_sg.dtsi:31 */
				status = "disabled";                   /* in zephyr\dts\arm\microchip\pic32c\pic32ck_sg_gc\common\pic32ck_sg.dtsi:32 */
			};

			/* node '/soc/pinctrl@44800000/gpio@44801180' defined in zephyr\dts\arm\microchip\pic32c\pic32ck_sg_gc\common\pic32ck_sg.dtsi:35 */
			portd_secure: gpio@44801180 {
				compatible = "microchip,port-g1-gpio"; /* in zephyr\dts\arm\microchip\pic32c\pic32ck_sg_gc\common\pic32ck_sg.dtsi:36 */
				reg = < 0x44801180 0x80 >;             /* in zephyr\dts\arm\microchip\pic32c\pic32ck_sg_gc\common\pic32ck_sg.dtsi:37 */
				gpio-controller;                       /* in zephyr\dts\arm\microchip\pic32c\pic32ck_sg_gc\common\pic32ck_sg.dtsi:38 */
				#gpio-cells = < 0x2 >;                 /* in zephyr\dts\arm\microchip\pic32c\pic32ck_sg_gc\common\pic32ck_sg.dtsi:39 */
				#microchip,pin-cells = < 0x2 >;        /* in zephyr\dts\arm\microchip\pic32c\pic32ck_sg_gc\common\pic32ck_sg.dtsi:40 */
				status = "okay";                       /* in zephyr\boards\microchip\pic32c\pic32ck_sg01_cult\pic32ck_sg01_cult.dts:368 */
				phandle = < 0x11 >;                    /* in zephyr\boards\microchip\pic32c\pic32ck_sg01_cult\pic32ck_sg01_cult.dts:43 */
			};

			/* node '/soc/pinctrl@44800000/sercom1_uart_default' defined in zephyr\boards\microchip\pic32c\pic32ck_sg01_cult\pic32ck_sg01_cult-pinctrl.dtsi:10 */
			sercom1_uart_default: sercom1_uart_default {

				/* node '/soc/pinctrl@44800000/sercom1_uart_default/group1' defined in zephyr\boards\microchip\pic32c\pic32ck_sg01_cult\pic32ck_sg01_cult-pinctrl.dtsi:11 */
				group1 {
					pinmux = < 0x22d3 >,
					         < 0x22e3 >; /* in zephyr\boards\microchip\pic32c\pic32ck_sg01_cult\pic32ck_sg01_cult-pinctrl.dtsi:12 */
				};
			};

			/* node '/soc/pinctrl@44800000/sercom2_spi_default' defined in zephyr\boards\microchip\pic32c\pic32ck_sg01_cult\pic32ck_sg01_cult-pinctrl.dtsi:17 */
			sercom2_spi_default: sercom2_spi_default {
				phandle = < 0x6 >; /* in zephyr\boards\microchip\pic32c\pic32ck_sg01_cult\pic32ck_sg01_cult.dts:432 */

				/* node '/soc/pinctrl@44800000/sercom2_spi_default/group1' defined in zephyr\boards\microchip\pic32c\pic32ck_sg01_cult\pic32ck_sg01_cult-pinctrl.dtsi:18 */
				group1 {
					pinmux = < 0x22f2 >,
					         < 0x2322 >,
					         < 0x2312 >,
					         < 0x2302 >; /* in zephyr\boards\microchip\pic32c\pic32ck_sg01_cult\pic32ck_sg01_cult-pinctrl.dtsi:19 */
				};
			};

			/* node '/soc/pinctrl@44800000/sercom3_uart_default' defined in zephyr\boards\microchip\pic32c\pic32ck_sg01_cult\pic32ck_sg01_cult-pinctrl.dtsi:26 */
			sercom3_uart_default: sercom3_uart_default {

				/* node '/soc/pinctrl@44800000/sercom3_uart_default/group1' defined in zephyr\boards\microchip\pic32c\pic32ck_sg01_cult\pic32ck_sg01_cult-pinctrl.dtsi:27 */
				group1 {
					pinmux = < 0x2351 >,
					         < 0x2361 >; /* in zephyr\boards\microchip\pic32c\pic32ck_sg01_cult\pic32ck_sg01_cult-pinctrl.dtsi:28 */
				};
			};

			/* node '/soc/pinctrl@44800000/sercom4_i2c_default' defined in zephyr\boards\microchip\pic32c\pic32ck_sg01_cult\pic32ck_sg01_cult-pinctrl.dtsi:33 */
			sercom4_i2c_default: sercom4_i2c_default {
				phandle = < 0x7 >; /* in zephyr\boards\microchip\pic32c\pic32ck_sg01_cult\pic32ck_sg01_cult.dts:376 */

				/* node '/soc/pinctrl@44800000/sercom4_i2c_default/group1' defined in zephyr\boards\microchip\pic32c\pic32ck_sg01_cult\pic32ck_sg01_cult-pinctrl.dtsi:34 */
				group1 {
					pinmux = < 0x2291 >,
					         < 0x22a1 >; /* in zephyr\boards\microchip\pic32c\pic32ck_sg01_cult\pic32ck_sg01_cult-pinctrl.dtsi:35 */
				};
			};

			/* node '/soc/pinctrl@44800000/sercom5_uart_default' defined in zephyr\boards\microchip\pic32c\pic32ck_sg01_cult\pic32ck_sg01_cult-pinctrl.dtsi:40 */
			sercom5_uart_default: sercom5_uart_default {
				phandle = < 0x8 >; /* in zephyr\boards\microchip\pic32c\pic32ck_sg01_cult\pic32ck_sg01_cult.dts:411 */

				/* node '/soc/pinctrl@44800000/sercom5_uart_default/group1' defined in zephyr\boards\microchip\pic32c\pic32ck_sg01_cult\pic32ck_sg01_cult-pinctrl.dtsi:41 */
				group1 {
					pinmux = < 0x2390 >,
					         < 0x2380 >; /* in zephyr\boards\microchip\pic32c\pic32ck_sg01_cult\pic32ck_sg01_cult-pinctrl.dtsi:42 */
				};
			};

			/* node '/soc/pinctrl@44800000/can0_default' defined in zephyr\boards\microchip\pic32c\pic32ck_sg01_cult\pic32ck_sg01_cult-pinctrl.dtsi:48 */
			can0_default: can0_default {
				phandle = < 0xc >; /* in zephyr\boards\microchip\pic32c\pic32ck_sg01_cult\pic32ck_sg01_cult.dts:421 */

				/* node '/soc/pinctrl@44800000/can0_default/group1' defined in zephyr\boards\microchip\pic32c\pic32ck_sg01_cult\pic32ck_sg01_cult-pinctrl.dtsi:49 */
				group1 {
					pinmux = < 0x7301 >,
					         < 0x7311 >; /* in zephyr\boards\microchip\pic32c\pic32ck_sg01_cult\pic32ck_sg01_cult-pinctrl.dtsi:50 */
				};
			};

			/* node '/soc/pinctrl@44800000/sercom2_spi_ext1' defined in zephyr\boards\microchip\pic32c\pic32ck_sg01_cult\pic32ck_sg01_cult-pinctrl.dtsi:55 */
			sercom2_spi_ext1: sercom2_spi_ext1 {

				/* node '/soc/pinctrl@44800000/sercom2_spi_ext1/group1' defined in zephyr\boards\microchip\pic32c\pic32ck_sg01_cult\pic32ck_sg01_cult-pinctrl.dtsi:56 */
				group1 {
					pinmux = < 0x22f2 >,
					         < 0x2302 >,
					         < 0x2312 >; /* in zephyr\boards\microchip\pic32c\pic32ck_sg01_cult\pic32ck_sg01_cult-pinctrl.dtsi:57 */
				};

				/* node '/soc/pinctrl@44800000/sercom2_spi_ext1/group2' defined in zephyr\boards\microchip\pic32c\pic32ck_sg01_cult\pic32ck_sg01_cult-pinctrl.dtsi:62 */
				group2 {
					pinmux = < 0xf3 >; /* in zephyr\boards\microchip\pic32c\pic32ck_sg01_cult\pic32ck_sg01_cult-pinctrl.dtsi:63 */
				};
			};

			/* node '/soc/pinctrl@44800000/sercom2_spi_ext2' defined in zephyr\boards\microchip\pic32c\pic32ck_sg01_cult\pic32ck_sg01_cult-pinctrl.dtsi:67 */
			sercom2_spi_ext2: sercom2_spi_ext2 {

				/* node '/soc/pinctrl@44800000/sercom2_spi_ext2/group1' defined in zephyr\boards\microchip\pic32c\pic32ck_sg01_cult\pic32ck_sg01_cult-pinctrl.dtsi:68 */
				group1 {
					pinmux = < 0x22f2 >,
					         < 0x2302 >,
					         < 0x2312 >; /* in zephyr\boards\microchip\pic32c\pic32ck_sg01_cult\pic32ck_sg01_cult-pinctrl.dtsi:69 */
				};

				/* node '/soc/pinctrl@44800000/sercom2_spi_ext2/group2' defined in zephyr\boards\microchip\pic32c\pic32ck_sg01_cult\pic32ck_sg01_cult-pinctrl.dtsi:74 */
				group2 {
					pinmux = < 0x172 >; /* in zephyr\boards\microchip\pic32c\pic32ck_sg01_cult\pic32ck_sg01_cult-pinctrl.dtsi:75 */
				};
			};

			/* node '/soc/pinctrl@44800000/sercom2_spi_arduino' defined in zephyr\boards\microchip\pic32c\pic32ck_sg01_cult\pic32ck_sg01_cult-pinctrl.dtsi:79 */
			sercom2_spi_arduino: sercom2_spi_arduino {

				/* node '/soc/pinctrl@44800000/sercom2_spi_arduino/group1' defined in zephyr\boards\microchip\pic32c\pic32ck_sg01_cult\pic32ck_sg01_cult-pinctrl.dtsi:80 */
				group1 {
					pinmux = < 0x22f2 >,
					         < 0x2302 >,
					         < 0x2312 >; /* in zephyr\boards\microchip\pic32c\pic32ck_sg01_cult\pic32ck_sg01_cult-pinctrl.dtsi:81 */
				};

				/* node '/soc/pinctrl@44800000/sercom2_spi_arduino/group2' defined in zephyr\boards\microchip\pic32c\pic32ck_sg01_cult\pic32ck_sg01_cult-pinctrl.dtsi:86 */
				group2 {
					pinmux = < 0xc1 >; /* in zephyr\boards\microchip\pic32c\pic32ck_sg01_cult\pic32ck_sg01_cult-pinctrl.dtsi:87 */
				};
			};

			/* node '/soc/pinctrl@44800000/sercom2_spi_mikrobus' defined in zephyr\boards\microchip\pic32c\pic32ck_sg01_cult\pic32ck_sg01_cult-pinctrl.dtsi:91 */
			sercom2_spi_mikrobus: sercom2_spi_mikrobus {

				/* node '/soc/pinctrl@44800000/sercom2_spi_mikrobus/group1' defined in zephyr\boards\microchip\pic32c\pic32ck_sg01_cult\pic32ck_sg01_cult-pinctrl.dtsi:92 */
				group1 {
					pinmux = < 0x22f2 >,
					         < 0x2302 >,
					         < 0x2312 >; /* in zephyr\boards\microchip\pic32c\pic32ck_sg01_cult\pic32ck_sg01_cult-pinctrl.dtsi:93 */
				};

				/* node '/soc/pinctrl@44800000/sercom2_spi_mikrobus/group2' defined in zephyr\boards\microchip\pic32c\pic32ck_sg01_cult\pic32ck_sg01_cult-pinctrl.dtsi:98 */
				group2 {
					pinmux = < 0xf3 >; /* in zephyr\boards\microchip\pic32c\pic32ck_sg01_cult\pic32ck_sg01_cult-pinctrl.dtsi:99 */
				};
			};

			/* node '/soc/pinctrl@44800000/sercom_audio_spi' defined in zephyr\boards\microchip\pic32c\pic32ck_sg01_cult\pic32ck_sg01_cult-pinctrl.dtsi:103 */
			sercom_audio_spi: sercom_audio_spi {

				/* node '/soc/pinctrl@44800000/sercom_audio_spi/group1' defined in zephyr\boards\microchip\pic32c\pic32ck_sg01_cult\pic32ck_sg01_cult-pinctrl.dtsi:104 */
				group1 {
					pinmux = < 0x9303 >,
					         < 0x9313 >,
					         < 0x92e3 >,
					         < 0x92d3 >; /* in zephyr\boards\microchip\pic32c\pic32ck_sg01_cult\pic32ck_sg01_cult-pinctrl.dtsi:105 */
				};
			};

			/* node '/soc/pinctrl@44800000/sercom4_spi_default' defined in zephyr\boards\microchip\pic32c\pic32ck_sg01_cult\pic32ck_sg01_cult-pinctrl.dtsi:112 */
			sercom4_spi_default: sercom4_spi_default {

				/* node '/soc/pinctrl@44800000/sercom4_spi_default/group1' defined in zephyr\boards\microchip\pic32c\pic32ck_sg01_cult\pic32ck_sg01_cult-pinctrl.dtsi:113 */
				group1 {
					pinmux = < 0x2291 >,
					         < 0x2261 >,
					         < 0x22d1 >,
					         < 0x22a1 >; /* in zephyr\boards\microchip\pic32c\pic32ck_sg01_cult\pic32ck_sg01_cult-pinctrl.dtsi:114 */
				};
			};

			/* node '/soc/pinctrl@44800000/usb_dc_default' defined in zephyr\boards\microchip\pic32c\pic32ck_sg01_cult\pic32ck_sg01_cult-pinctrl.dtsi:121 */
			usb_dc_default: usb_dc_default {
				phandle = < 0xa >; /* in zephyr\boards\microchip\pic32c\pic32ck_sg01_cult\pic32ck_sg01_cult.dts:438 */

				/* node '/soc/pinctrl@44800000/usb_dc_default/group1' defined in zephyr\boards\microchip\pic32c\pic32ck_sg01_cult\pic32ck_sg01_cult-pinctrl.dtsi:122 */
				group1 {
					pinmux = < 0x7243 >,
					         < 0x7233 >; /* in zephyr\boards\microchip\pic32c\pic32ck_sg01_cult\pic32ck_sg01_cult-pinctrl.dtsi:123 */
				};
			};

			/* node '/soc/pinctrl@44800000/mdio_default' defined in zephyr\boards\microchip\pic32c\pic32ck_sg01_cult\pic32ck_sg01_cult-pinctrl.dtsi:128 */
			mdio_default: mdio_default {
				phandle = < 0x10 >; /* in zephyr\boards\microchip\pic32c\pic32ck_sg01_cult\pic32ck_sg01_cult.dts:479 */

				/* node '/soc/pinctrl@44800000/mdio_default/group1' defined in zephyr\boards\microchip\pic32c\pic32ck_sg01_cult\pic32ck_sg01_cult-pinctrl.dtsi:129 */
				group1 {
					pinmux = < 0xb232 >,
					         < 0xb242 >; /* in zephyr\boards\microchip\pic32c\pic32ck_sg01_cult\pic32ck_sg01_cult-pinctrl.dtsi:130 */
				};
			};

			/* node '/soc/pinctrl@44800000/gmac_rmii' defined in zephyr\boards\microchip\pic32c\pic32ck_sg01_cult\pic32ck_sg01_cult-pinctrl.dtsi:135 */
			gmac_rmii: gmac_rmii {
				phandle = < 0xd >; /* in zephyr\boards\microchip\pic32c\pic32ck_sg01_cult\pic32ck_sg01_cult.dts:468 */

				/* node '/soc/pinctrl@44800000/gmac_rmii/group1' defined in zephyr\boards\microchip\pic32c\pic32ck_sg01_cult\pic32ck_sg01_cult-pinctrl.dtsi:136 */
				group1 {
					pinmux = < 0xb202 >,
					         < 0xb2b2 >,
					         < 0xb2c2 >,
					         < 0xb2d2 >,
					         < 0xb2a2 >,
					         < 0xb272 >,
					         < 0xb262 >,
					         < 0xb292 >; /* in zephyr\boards\microchip\pic32c\pic32ck_sg01_cult\pic32ck_sg01_cult-pinctrl.dtsi:137 */
				};
			};

			/* node '/soc/pinctrl@44800000/sdmmc0_default' defined in zephyr\boards\microchip\pic32c\pic32ck_sg01_cult\pic32ck_sg01_cult-pinctrl.dtsi:148 */
			sdhc0_default: sdmmc0_default {
				phandle = < 0xb >; /* in zephyr\boards\microchip\pic32c\pic32ck_sg01_cult\pic32ck_sg01_cult.dts:492 */

				/* node '/soc/pinctrl@44800000/sdmmc0_default/group1' defined in zephyr\boards\microchip\pic32c\pic32ck_sg01_cult\pic32ck_sg01_cult-pinctrl.dtsi:149 */
				group1 {
					pinmux = < 0x82a3 >,
					         < 0x8263 >,
					         < 0x8273 >,
					         < 0x82b3 >,
					         < 0x8283 >,
					         < 0x8293 >,
					         < 0x82c3 >,
					         < 0x8253 >; /* in zephyr\boards\microchip\pic32c\pic32ck_sg01_cult\pic32ck_sg01_cult-pinctrl.dtsi:150 */
				};
			};
		};

		/* node '/soc/sercom@44810000' defined in zephyr\dts\arm\microchip\pic32c\pic32ck_sg_gc\common\pic32ck_sg_gc.dtsi:235 */
		sercom0: sercom@44810000 {
			compatible = "microchip,sercom-g1";  /* in zephyr\dts\arm\microchip\pic32c\pic32ck_sg_gc\common\pic32ck_sg_gc.dtsi:236 */
			reg = < 0x44810000 0x38 >;           /* in zephyr\dts\arm\microchip\pic32c\pic32ck_sg_gc\common\pic32ck_sg_gc.dtsi:237 */
			interrupts = < 0x2c 0x0 >,
			             < 0x2d 0x0 >,
			             < 0x2e 0x0 >,
			             < 0x2f 0x0 >,
			             < 0x30 0x0 >,
			             < 0x31 0x0 >;           /* in zephyr\dts\arm\microchip\pic32c\pic32ck_sg_gc\common\pic32ck_sg_gc.dtsi:238 */
			interrupt-names = "error",
			                  "dre",
			                  "txc",
			                  "rxc",
			                  "rxs",
			                  "ctsic";           /* in zephyr\dts\arm\microchip\pic32c\pic32ck_sg_gc\common\pic32ck_sg_gc.dtsi:239 */
			clocks = < &mclkperiph 0x2421ff25 >,
			         < &gclkperiph 0x1fffd31a >; /* in zephyr\dts\arm\microchip\pic32c\pic32ck_sg_gc\common\pic32ck_sg_gc.dtsi:240 */
			clock-names = "mclk",
			              "gclk";                /* in zephyr\dts\arm\microchip\pic32c\pic32ck_sg_gc\common\pic32ck_sg_gc.dtsi:242 */
			status = "disabled";                 /* in zephyr\dts\arm\microchip\pic32c\pic32ck_sg_gc\common\pic32ck_sg_gc.dtsi:243 */
		};

		/* node '/soc/sercom@44812000' defined in zephyr\dts\arm\microchip\pic32c\pic32ck_sg_gc\common\pic32ck_sg_gc.dtsi:246 */
		sercom1: sercom@44812000 {
			compatible = "microchip,sercom-g1";  /* in zephyr\dts\arm\microchip\pic32c\pic32ck_sg_gc\common\pic32ck_sg_gc.dtsi:247 */
			reg = < 0x44812000 0x38 >;           /* in zephyr\dts\arm\microchip\pic32c\pic32ck_sg_gc\common\pic32ck_sg_gc.dtsi:248 */
			interrupts = < 0x32 0x0 >,
			             < 0x33 0x0 >,
			             < 0x34 0x0 >,
			             < 0x35 0x0 >,
			             < 0x36 0x0 >,
			             < 0x37 0x0 >;           /* in zephyr\dts\arm\microchip\pic32c\pic32ck_sg_gc\common\pic32ck_sg_gc.dtsi:249 */
			interrupt-names = "error",
			                  "dre",
			                  "txc",
			                  "rxc",
			                  "rxs",
			                  "ctsic";           /* in zephyr\dts\arm\microchip\pic32c\pic32ck_sg_gc\common\pic32ck_sg_gc.dtsi:250 */
			clocks = < &mclkperiph 0x24223f26 >,
			         < &gclkperiph 0x1fffd41b >; /* in zephyr\dts\arm\microchip\pic32c\pic32ck_sg_gc\common\pic32ck_sg_gc.dtsi:251 */
			clock-names = "mclk",
			              "gclk";                /* in zephyr\dts\arm\microchip\pic32c\pic32ck_sg_gc\common\pic32ck_sg_gc.dtsi:253 */
			status = "disabled";                 /* in zephyr\dts\arm\microchip\pic32c\pic32ck_sg_gc\common\pic32ck_sg_gc.dtsi:254 */
		};

		/* node '/soc/sercom@44814000' defined in zephyr\dts\arm\microchip\pic32c\pic32ck_sg_gc\common\pic32ck_sg_gc.dtsi:257 */
		sercom2: sercom@44814000 {
			reg = < 0x44814000 0x38 >;              /* in zephyr\dts\arm\microchip\pic32c\pic32ck_sg_gc\common\pic32ck_sg_gc.dtsi:259 */
			interrupts = < 0x38 0x0 >,
			             < 0x39 0x0 >,
			             < 0x3a 0x0 >,
			             < 0x3b 0x0 >,
			             < 0x3c 0x0 >,
			             < 0x3d 0x0 >;              /* in zephyr\dts\arm\microchip\pic32c\pic32ck_sg_gc\common\pic32ck_sg_gc.dtsi:260 */
			interrupt-names = "error",
			                  "dre",
			                  "txc",
			                  "rxc",
			                  "rxs",
			                  "ctsic";              /* in zephyr\dts\arm\microchip\pic32c\pic32ck_sg_gc\common\pic32ck_sg_gc.dtsi:261 */
			clocks = < &mclkperiph 0x24227f27 >,
			         < &gclkperiph 0x1fffd51c >;    /* in zephyr\dts\arm\microchip\pic32c\pic32ck_sg_gc\common\pic32ck_sg_gc.dtsi:262 */
			clock-names = "mclk",
			              "gclk";                   /* in zephyr\dts\arm\microchip\pic32c\pic32ck_sg_gc\common\pic32ck_sg_gc.dtsi:264 */
			compatible = "microchip,sercom-g1-spi"; /* in zephyr\boards\microchip\pic32c\pic32ck_sg01_cult\pic32ck_sg01_cult.dts:427 */
			dipo = < 0x3 >;                         /* in zephyr\boards\microchip\pic32c\pic32ck_sg01_cult\pic32ck_sg01_cult.dts:428 */
			dopo = < 0x0 >;                         /* in zephyr\boards\microchip\pic32c\pic32ck_sg01_cult\pic32ck_sg01_cult.dts:429 */
			#address-cells = < 0x1 >;               /* in zephyr\boards\microchip\pic32c\pic32ck_sg01_cult\pic32ck_sg01_cult.dts:430 */
			#size-cells = < 0x0 >;                  /* in zephyr\boards\microchip\pic32c\pic32ck_sg01_cult\pic32ck_sg01_cult.dts:431 */
			pinctrl-0 = < &sercom2_spi_default >;   /* in zephyr\boards\microchip\pic32c\pic32ck_sg01_cult\pic32ck_sg01_cult.dts:432 */
			pinctrl-names = "default";              /* in zephyr\boards\microchip\pic32c\pic32ck_sg01_cult\pic32ck_sg01_cult.dts:433 */
			status = "okay";                        /* in zephyr\boards\microchip\pic32c\pic32ck_sg01_cult\pic32ck_sg01_cult.dts:434 */
		};

		/* node '/soc/sercom@44816000' defined in zephyr\dts\arm\microchip\pic32c\pic32ck_sg_gc\common\pic32ck_sg_gc.dtsi:268 */
		sercom3: sercom@44816000 {
			compatible = "microchip,sercom-g1";  /* in zephyr\dts\arm\microchip\pic32c\pic32ck_sg_gc\common\pic32ck_sg_gc.dtsi:269 */
			reg = < 0x44816000 0x38 >;           /* in zephyr\dts\arm\microchip\pic32c\pic32ck_sg_gc\common\pic32ck_sg_gc.dtsi:270 */
			interrupts = < 0x3e 0x0 >,
			             < 0x3f 0x0 >,
			             < 0x40 0x0 >,
			             < 0x41 0x0 >,
			             < 0x42 0x0 >,
			             < 0x43 0x0 >;           /* in zephyr\dts\arm\microchip\pic32c\pic32ck_sg_gc\common\pic32ck_sg_gc.dtsi:271 */
			interrupt-names = "error",
			                  "dre",
			                  "txc",
			                  "rxc",
			                  "rxs",
			                  "ctsic";           /* in zephyr\dts\arm\microchip\pic32c\pic32ck_sg_gc\common\pic32ck_sg_gc.dtsi:272 */
			clocks = < &mclkperiph 0x2422bf28 >,
			         < &gclkperiph 0x1fffd61d >; /* in zephyr\dts\arm\microchip\pic32c\pic32ck_sg_gc\common\pic32ck_sg_gc.dtsi:273 */
			clock-names = "mclk",
			              "gclk";                /* in zephyr\dts\arm\microchip\pic32c\pic32ck_sg_gc\common\pic32ck_sg_gc.dtsi:275 */
			status = "disabled";                 /* in zephyr\dts\arm\microchip\pic32c\pic32ck_sg_gc\common\pic32ck_sg_gc.dtsi:276 */
		};

		/* node '/soc/tcc@44818000' defined in zephyr\dts\arm\microchip\pic32c\pic32ck_sg_gc\common\pic32ck_sg_gc.dtsi:279 */
		tcc0: tcc@44818000 {
			compatible = "microchip,tcc-g1";     /* in zephyr\dts\arm\microchip\pic32c\pic32ck_sg_gc\common\pic32ck_sg_gc.dtsi:280 */
			reg = < 0x44818000 0x88 >;           /* in zephyr\dts\arm\microchip\pic32c\pic32ck_sg_gc\common\pic32ck_sg_gc.dtsi:281 */
			interrupts = < 0x44 0x0 >,
			             < 0x45 0x0 >,
			             < 0x46 0x0 >,
			             < 0x47 0x0 >,
			             < 0x48 0x0 >,
			             < 0x49 0x0 >,
			             < 0x4a 0x0 >;           /* in zephyr\dts\arm\microchip\pic32c\pic32ck_sg_gc\common\pic32ck_sg_gc.dtsi:282 */
			interrupt-names = "cnt",
			                  "mc0",
			                  "mc1",
			                  "mc2",
			                  "mc3",
			                  "mc4",
			                  "mc5";             /* in zephyr\dts\arm\microchip\pic32c\pic32ck_sg_gc\common\pic32ck_sg_gc.dtsi:283 */
			clocks = < &mclkperiph 0x2422ff29 >,
			         < &gclkperiph 0x1fffd71e >; /* in zephyr\dts\arm\microchip\pic32c\pic32ck_sg_gc\common\pic32ck_sg_gc.dtsi:284 */
			clock-names = "mclk",
			              "gclk";                /* in zephyr\dts\arm\microchip\pic32c\pic32ck_sg_gc\common\pic32ck_sg_gc.dtsi:286 */
			max-bit-width = < 0x20 >;            /* in zephyr\dts\arm\microchip\pic32c\pic32ck_sg_gc\common\pic32ck_sg_gc.dtsi:287 */
			channels = < 0x6 >;                  /* in zephyr\dts\arm\microchip\pic32c\pic32ck_sg_gc\common\pic32ck_sg_gc.dtsi:288 */
			status = "disabled";                 /* in zephyr\dts\arm\microchip\pic32c\pic32ck_sg_gc\common\pic32ck_sg_gc.dtsi:289 */
		};

		/* node '/soc/tcc@4481a000' defined in zephyr\dts\arm\microchip\pic32c\pic32ck_sg_gc\common\pic32ck_sg_gc.dtsi:292 */
		tcc1: tcc@4481a000 {
			reg = < 0x4481a000 0x88 >;               /* in zephyr\dts\arm\microchip\pic32c\pic32ck_sg_gc\common\pic32ck_sg_gc.dtsi:294 */
			interrupts = < 0x4b 0x0 >,
			             < 0x4c 0x0 >,
			             < 0x4d 0x0 >,
			             < 0x4e 0x0 >,
			             < 0x4f 0x0 >,
			             < 0x50 0x0 >,
			             < 0x51 0x0 >;               /* in zephyr\dts\arm\microchip\pic32c\pic32ck_sg_gc\common\pic32ck_sg_gc.dtsi:295 */
			interrupt-names = "cnt",
			                  "mc0",
			                  "mc1",
			                  "mc2",
			                  "mc3",
			                  "mc4",
			                  "mc5";                 /* in zephyr\dts\arm\microchip\pic32c\pic32ck_sg_gc\common\pic32ck_sg_gc.dtsi:296 */
			clocks = < &mclkperiph 0x24233f2a >,
			         < &gclkperiph 0x1fffd71f >;     /* in zephyr\dts\arm\microchip\pic32c\pic32ck_sg_gc\common\pic32ck_sg_gc.dtsi:297 */
			clock-names = "mclk",
			              "gclk";                    /* in zephyr\dts\arm\microchip\pic32c\pic32ck_sg_gc\common\pic32ck_sg_gc.dtsi:299 */
			channels = < 0x6 >;                      /* in zephyr\dts\arm\microchip\pic32c\pic32ck_sg_gc\common\pic32ck_sg_gc.dtsi:301 */
			compatible = "microchip,tcc-g1-counter"; /* in zephyr\boards\microchip\pic32c\pic32ck_sg01_cult\pic32ck_sg01_cult.dts:357 */
			max-bit-width = < 0x20 >;                /* in zephyr\boards\microchip\pic32c\pic32ck_sg01_cult\pic32ck_sg01_cult.dts:358 */
			prescaler = < 0x8 >;                     /* in zephyr\boards\microchip\pic32c\pic32ck_sg01_cult\pic32ck_sg01_cult.dts:359 */
			status = "okay";                         /* in zephyr\boards\microchip\pic32c\pic32ck_sg01_cult\pic32ck_sg01_cult.dts:360 */
		};

		/* node '/soc/tcc@4481c000' defined in zephyr\dts\arm\microchip\pic32c\pic32ck_sg_gc\common\pic32ck_sg_gc.dtsi:305 */
		tcc2: tcc@4481c000 {
			compatible = "microchip,tcc-g1";     /* in zephyr\dts\arm\microchip\pic32c\pic32ck_sg_gc\common\pic32ck_sg_gc.dtsi:306 */
			reg = < 0x4481c000 0x88 >;           /* in zephyr\dts\arm\microchip\pic32c\pic32ck_sg_gc\common\pic32ck_sg_gc.dtsi:307 */
			interrupts = < 0x52 0x0 >,
			             < 0x53 0x0 >,
			             < 0x54 0x0 >,
			             < 0x55 0x0 >,
			             < 0x56 0x0 >,
			             < 0x57 0x0 >,
			             < 0x58 0x0 >;           /* in zephyr\dts\arm\microchip\pic32c\pic32ck_sg_gc\common\pic32ck_sg_gc.dtsi:308 */
			interrupt-names = "cnt",
			                  "mc0",
			                  "mc1",
			                  "mc2",
			                  "mc3",
			                  "mc4",
			                  "mc5";             /* in zephyr\dts\arm\microchip\pic32c\pic32ck_sg_gc\common\pic32ck_sg_gc.dtsi:309 */
			clocks = < &mclkperiph 0x24237f2b >,
			         < &gclkperiph 0x1fffd820 >; /* in zephyr\dts\arm\microchip\pic32c\pic32ck_sg_gc\common\pic32ck_sg_gc.dtsi:310 */
			clock-names = "mclk",
			              "gclk";                /* in zephyr\dts\arm\microchip\pic32c\pic32ck_sg_gc\common\pic32ck_sg_gc.dtsi:312 */
			max-bit-width = < 0x20 >;            /* in zephyr\dts\arm\microchip\pic32c\pic32ck_sg_gc\common\pic32ck_sg_gc.dtsi:313 */
			channels = < 0x6 >;                  /* in zephyr\dts\arm\microchip\pic32c\pic32ck_sg_gc\common\pic32ck_sg_gc.dtsi:314 */
			status = "disabled";                 /* in zephyr\dts\arm\microchip\pic32c\pic32ck_sg_gc\common\pic32ck_sg_gc.dtsi:315 */
		};

		/* node '/soc/tcc@4481e000' defined in zephyr\dts\arm\microchip\pic32c\pic32ck_sg_gc\common\pic32ck_sg_gc.dtsi:318 */
		tcc3: tcc@4481e000 {
			compatible = "microchip,tcc-g1";     /* in zephyr\dts\arm\microchip\pic32c\pic32ck_sg_gc\common\pic32ck_sg_gc.dtsi:319 */
			reg = < 0x4481e000 0x88 >;           /* in zephyr\dts\arm\microchip\pic32c\pic32ck_sg_gc\common\pic32ck_sg_gc.dtsi:320 */
			interrupts = < 0x59 0x0 >,
			             < 0x5a 0x0 >,
			             < 0x5b 0x0 >,
			             < 0x5c 0x0 >,
			             < 0x5d 0x0 >,
			             < 0x5e 0x0 >,
			             < 0x5f 0x0 >;           /* in zephyr\dts\arm\microchip\pic32c\pic32ck_sg_gc\common\pic32ck_sg_gc.dtsi:321 */
			interrupt-names = "cnt",
			                  "mc0",
			                  "mc1",
			                  "mc2",
			                  "mc3",
			                  "mc4",
			                  "mc5";             /* in zephyr\dts\arm\microchip\pic32c\pic32ck_sg_gc\common\pic32ck_sg_gc.dtsi:322 */
			clocks = < &mclkperiph 0x2423bf2c >,
			         < &gclkperiph 0x1fffd821 >; /* in zephyr\dts\arm\microchip\pic32c\pic32ck_sg_gc\common\pic32ck_sg_gc.dtsi:323 */
			clock-names = "mclk",
			              "gclk";                /* in zephyr\dts\arm\microchip\pic32c\pic32ck_sg_gc\common\pic32ck_sg_gc.dtsi:325 */
			max-bit-width = < 0x20 >;            /* in zephyr\dts\arm\microchip\pic32c\pic32ck_sg_gc\common\pic32ck_sg_gc.dtsi:326 */
			channels = < 0x6 >;                  /* in zephyr\dts\arm\microchip\pic32c\pic32ck_sg_gc\common\pic32ck_sg_gc.dtsi:327 */
			status = "disabled";                 /* in zephyr\dts\arm\microchip\pic32c\pic32ck_sg_gc\common\pic32ck_sg_gc.dtsi:328 */
		};

		/* node '/soc/sercom@45000000' defined in zephyr\dts\arm\microchip\pic32c\pic32ck_sg_gc\common\pic32ck_sg_gc.dtsi:331 */
		sercom4: sercom@45000000 {
			reg = < 0x45000000 0x38 >;              /* in zephyr\dts\arm\microchip\pic32c\pic32ck_sg_gc\common\pic32ck_sg_gc.dtsi:333 */
			interrupts = < 0x60 0x0 >,
			             < 0x61 0x0 >,
			             < 0x62 0x0 >,
			             < 0x63 0x0 >,
			             < 0x64 0x0 >,
			             < 0x65 0x0 >;              /* in zephyr\dts\arm\microchip\pic32c\pic32ck_sg_gc\common\pic32ck_sg_gc.dtsi:334 */
			interrupt-names = "error",
			                  "dre",
			                  "txc",
			                  "rxc",
			                  "rxs",
			                  "ctsic";              /* in zephyr\dts\arm\microchip\pic32c\pic32ck_sg_gc\common\pic32ck_sg_gc.dtsi:335 */
			clocks = < &mclkperiph 0x24303f2d >,
			         < &gclkperiph 0x1fffd922 >;    /* in zephyr\dts\arm\microchip\pic32c\pic32ck_sg_gc\common\pic32ck_sg_gc.dtsi:336 */
			clock-names = "mclk",
			              "gclk";                   /* in zephyr\dts\arm\microchip\pic32c\pic32ck_sg_gc\common\pic32ck_sg_gc.dtsi:338 */
			compatible = "microchip,sercom-g1-i2c"; /* in zephyr\boards\microchip\pic32c\pic32ck_sg01_cult\pic32ck_sg01_cult.dts:372 */
			#address-cells = < 0x1 >;               /* in zephyr\boards\microchip\pic32c\pic32ck_sg01_cult\pic32ck_sg01_cult.dts:373 */
			#size-cells = < 0x0 >;                  /* in zephyr\boards\microchip\pic32c\pic32ck_sg01_cult\pic32ck_sg01_cult.dts:374 */
			clock-frequency = < 0x61a80 >;          /* in zephyr\boards\microchip\pic32c\pic32ck_sg01_cult\pic32ck_sg01_cult.dts:375 */
			pinctrl-0 = < &sercom4_i2c_default >;   /* in zephyr\boards\microchip\pic32c\pic32ck_sg01_cult\pic32ck_sg01_cult.dts:376 */
			pinctrl-names = "default";              /* in zephyr\boards\microchip\pic32c\pic32ck_sg01_cult\pic32ck_sg01_cult.dts:377 */
			status = "okay";                        /* in zephyr\boards\microchip\pic32c\pic32ck_sg01_cult\pic32ck_sg01_cult.dts:378 */

			/* node '/soc/sercom@45000000/eeprom@5e' defined in zephyr\boards\microchip\pic32c\pic32ck_sg01_cult\pic32ck_sg01_cult.dts:380 */
			eeprom: eeprom@5e {
				compatible = "atmel,at24",
				             "atmel,24mac402"; /* in zephyr\boards\microchip\pic32c\pic32ck_sg01_cult\pic32ck_sg01_cult.dts:381 */
				reg = < 0x5e >;                /* in zephyr\boards\microchip\pic32c\pic32ck_sg01_cult\pic32ck_sg01_cult.dts:382 */
				size = < 0x100 >;              /* in zephyr\boards\microchip\pic32c\pic32ck_sg01_cult\pic32ck_sg01_cult.dts:383 */
				pagesize = < 0x10 >;           /* in zephyr\boards\microchip\pic32c\pic32ck_sg01_cult\pic32ck_sg01_cult.dts:384 */
				address-width = < 0x8 >;       /* in zephyr\boards\microchip\pic32c\pic32ck_sg01_cult\pic32ck_sg01_cult.dts:385 */
				timeout = < 0x5 >;             /* in zephyr\boards\microchip\pic32c\pic32ck_sg01_cult\pic32ck_sg01_cult.dts:386 */

				/* node '/soc/sercom@45000000/eeprom@5e/nvmem-layout' defined in zephyr\boards\microchip\pic32c\pic32ck_sg01_cult\pic32ck_sg01_cult.dts:388 */
				nvmem-layout {
					compatible = "fixed-layout"; /* in zephyr\boards\microchip\pic32c\pic32ck_sg01_cult\pic32ck_sg01_cult.dts:389 */
					#address-cells = < 0x1 >;    /* in zephyr\boards\microchip\pic32c\pic32ck_sg01_cult\pic32ck_sg01_cult.dts:390 */
					#size-cells = < 0x1 >;       /* in zephyr\boards\microchip\pic32c\pic32ck_sg01_cult\pic32ck_sg01_cult.dts:391 */

					/* node '/soc/sercom@45000000/eeprom@5e/nvmem-layout/mac-address@9a' defined in zephyr\boards\microchip\pic32c\pic32ck_sg01_cult\pic32ck_sg01_cult.dts:393 */
					mac_address: mac-address@9a {
						reg = < 0x9a 0x6 >;          /* in zephyr\boards\microchip\pic32c\pic32ck_sg01_cult\pic32ck_sg01_cult.dts:394 */
						#nvmem-cell-cells = < 0x0 >; /* in zephyr\boards\microchip\pic32c\pic32ck_sg01_cult\pic32ck_sg01_cult.dts:395 */
						phandle = < 0xe >;           /* in zephyr\boards\microchip\pic32c\pic32ck_sg01_cult\pic32ck_sg01_cult.dts:471 */
					};
				};
			};
		};

		/* node '/soc/sercom@45002000' defined in zephyr\dts\arm\microchip\pic32c\pic32ck_sg_gc\common\pic32ck_sg_gc.dtsi:342 */
		sercom5: sercom@45002000 {
			reg = < 0x45002000 0x38 >;               /* in zephyr\dts\arm\microchip\pic32c\pic32ck_sg_gc\common\pic32ck_sg_gc.dtsi:344 */
			interrupts = < 0x66 0x0 >,
			             < 0x67 0x0 >,
			             < 0x68 0x0 >,
			             < 0x69 0x0 >,
			             < 0x6a 0x0 >,
			             < 0x6b 0x0 >;               /* in zephyr\dts\arm\microchip\pic32c\pic32ck_sg_gc\common\pic32ck_sg_gc.dtsi:345 */
			interrupt-names = "error",
			                  "dre",
			                  "txc",
			                  "rxc",
			                  "rxs",
			                  "ctsic";               /* in zephyr\dts\arm\microchip\pic32c\pic32ck_sg_gc\common\pic32ck_sg_gc.dtsi:346 */
			clocks = < &mclkperiph 0x24307f2e >,
			         < &gclkperiph 0x1fffda23 >;     /* in zephyr\dts\arm\microchip\pic32c\pic32ck_sg_gc\common\pic32ck_sg_gc.dtsi:347 */
			clock-names = "mclk",
			              "gclk";                    /* in zephyr\dts\arm\microchip\pic32c\pic32ck_sg_gc\common\pic32ck_sg_gc.dtsi:349 */
			compatible = "microchip,sercom-g1-uart"; /* in zephyr\boards\microchip\pic32c\pic32ck_sg01_cult\pic32ck_sg01_cult.dts:402 */
			#address-cells = < 0x1 >;                /* in zephyr\boards\microchip\pic32c\pic32ck_sg01_cult\pic32ck_sg01_cult.dts:403 */
			#size-cells = < 0x0 >;                   /* in zephyr\boards\microchip\pic32c\pic32ck_sg01_cult\pic32ck_sg01_cult.dts:404 */
			current-speed = < 0x1c200 >;             /* in zephyr\boards\microchip\pic32c\pic32ck_sg01_cult\pic32ck_sg01_cult.dts:405 */
			data-bits = < 0x8 >;                     /* in zephyr\boards\microchip\pic32c\pic32ck_sg01_cult\pic32ck_sg01_cult.dts:406 */
			parity = "none";                         /* in zephyr\boards\microchip\pic32c\pic32ck_sg01_cult\pic32ck_sg01_cult.dts:407 */
			stop-bits = "1";                         /* in zephyr\boards\microchip\pic32c\pic32ck_sg01_cult\pic32ck_sg01_cult.dts:408 */
			rxpo = < 0x1 >;                          /* in zephyr\boards\microchip\pic32c\pic32ck_sg01_cult\pic32ck_sg01_cult.dts:409 */
			txpo = < 0x0 >;                          /* in zephyr\boards\microchip\pic32c\pic32ck_sg01_cult\pic32ck_sg01_cult.dts:410 */
			pinctrl-0 = < &sercom5_uart_default >;   /* in zephyr\boards\microchip\pic32c\pic32ck_sg01_cult\pic32ck_sg01_cult.dts:411 */
			pinctrl-names = "default";               /* in zephyr\boards\microchip\pic32c\pic32ck_sg01_cult\pic32ck_sg01_cult.dts:412 */
			status = "okay";                         /* in zephyr\boards\microchip\pic32c\pic32ck_sg01_cult\pic32ck_sg01_cult.dts:413 */
		};

		/* node '/soc/tcc@45008000' defined in zephyr\dts\arm\microchip\pic32c\pic32ck_sg_gc\common\pic32ck_sg_gc.dtsi:353 */
		tcc4: tcc@45008000 {
			compatible = "microchip,tcc-g1";     /* in zephyr\dts\arm\microchip\pic32c\pic32ck_sg_gc\common\pic32ck_sg_gc.dtsi:354 */
			reg = < 0x45008000 0x88 >;           /* in zephyr\dts\arm\microchip\pic32c\pic32ck_sg_gc\common\pic32ck_sg_gc.dtsi:355 */
			interrupts = < 0x78 0x0 >,
			             < 0x79 0x0 >,
			             < 0x7a 0x0 >;           /* in zephyr\dts\arm\microchip\pic32c\pic32ck_sg_gc\common\pic32ck_sg_gc.dtsi:356 */
			interrupt-names = "cnt",
			                  "mc0",
			                  "mc1";             /* in zephyr\dts\arm\microchip\pic32c\pic32ck_sg_gc\common\pic32ck_sg_gc.dtsi:357 */
			clocks = < &mclkperiph 0x24313f31 >,
			         < &gclkperiph 0x1fffdd26 >; /* in zephyr\dts\arm\microchip\pic32c\pic32ck_sg_gc\common\pic32ck_sg_gc.dtsi:358 */
			clock-names = "mclk",
			              "gclk";                /* in zephyr\dts\arm\microchip\pic32c\pic32ck_sg_gc\common\pic32ck_sg_gc.dtsi:360 */
			max-bit-width = < 0x10 >;            /* in zephyr\dts\arm\microchip\pic32c\pic32ck_sg_gc\common\pic32ck_sg_gc.dtsi:361 */
			channels = < 0x2 >;                  /* in zephyr\dts\arm\microchip\pic32c\pic32ck_sg_gc\common\pic32ck_sg_gc.dtsi:362 */
			status = "disabled";                 /* in zephyr\dts\arm\microchip\pic32c\pic32ck_sg_gc\common\pic32ck_sg_gc.dtsi:363 */
		};

		/* node '/soc/tcc@4500a000' defined in zephyr\dts\arm\microchip\pic32c\pic32ck_sg_gc\common\pic32ck_sg_gc.dtsi:366 */
		tcc5: tcc@4500a000 {
			compatible = "microchip,tcc-g1";     /* in zephyr\dts\arm\microchip\pic32c\pic32ck_sg_gc\common\pic32ck_sg_gc.dtsi:367 */
			reg = < 0x4500a000 0x88 >;           /* in zephyr\dts\arm\microchip\pic32c\pic32ck_sg_gc\common\pic32ck_sg_gc.dtsi:368 */
			interrupts = < 0x7b 0x0 >,
			             < 0x7c 0x0 >,
			             < 0x7d 0x0 >;           /* in zephyr\dts\arm\microchip\pic32c\pic32ck_sg_gc\common\pic32ck_sg_gc.dtsi:369 */
			interrupt-names = "cnt",
			                  "mc0",
			                  "mc1";             /* in zephyr\dts\arm\microchip\pic32c\pic32ck_sg_gc\common\pic32ck_sg_gc.dtsi:370 */
			clocks = < &mclkperiph 0x24317f32 >,
			         < &gclkperiph 0x1fffde27 >; /* in zephyr\dts\arm\microchip\pic32c\pic32ck_sg_gc\common\pic32ck_sg_gc.dtsi:371 */
			clock-names = "mclk",
			              "gclk";                /* in zephyr\dts\arm\microchip\pic32c\pic32ck_sg_gc\common\pic32ck_sg_gc.dtsi:373 */
			max-bit-width = < 0x10 >;            /* in zephyr\dts\arm\microchip\pic32c\pic32ck_sg_gc\common\pic32ck_sg_gc.dtsi:374 */
			channels = < 0x2 >;                  /* in zephyr\dts\arm\microchip\pic32c\pic32ck_sg_gc\common\pic32ck_sg_gc.dtsi:375 */
			status = "disabled";                 /* in zephyr\dts\arm\microchip\pic32c\pic32ck_sg_gc\common\pic32ck_sg_gc.dtsi:376 */
		};

		/* node '/soc/random@45024000' defined in zephyr\dts\arm\microchip\pic32c\pic32ck_sg_gc\common\pic32ck_sg_gc.dtsi:379 */
		trng: random@45024000 {
			compatible = "microchip,trng-g1-entropy"; /* in zephyr\dts\arm\microchip\pic32c\pic32ck_sg_gc\common\pic32ck_sg_gc.dtsi:380 */
			reg = < 0x45024000 0x24 >;                /* in zephyr\dts\arm\microchip\pic32c\pic32ck_sg_gc\common\pic32ck_sg_gc.dtsi:381 */
			interrupts = < 0x93 0x0 >;                /* in zephyr\dts\arm\microchip\pic32c\pic32ck_sg_gc\common\pic32ck_sg_gc.dtsi:382 */
			interrupt-names = "datardy";              /* in zephyr\dts\arm\microchip\pic32c\pic32ck_sg_gc\common\pic32ck_sg_gc.dtsi:383 */
			clocks = < &mclkperiph 0x24343f3d >;      /* in zephyr\dts\arm\microchip\pic32c\pic32ck_sg_gc\common\pic32ck_sg_gc.dtsi:384 */
			clock-names = "mclk";                     /* in zephyr\dts\arm\microchip\pic32c\pic32ck_sg_gc\common\pic32ck_sg_gc.dtsi:385 */
			status = "okay";                          /* in zephyr\boards\microchip\pic32c\pic32ck_sg01_cult\pic32ck_sg01_cult.dts:417 */
		};

		/* node '/soc/adc@45010000' defined in zephyr\dts\arm\microchip\pic32c\pic32ck_sg_gc\common\pic32ck_sg_gc.dtsi:389 */
		adc0: adc@45010000 {
			compatible = "microchip,adc-g2";     /* in zephyr\dts\arm\microchip\pic32c\pic32ck_sg_gc\common\pic32ck_sg_gc.dtsi:390 */
			reg = < 0x45010000 0x5b >,
			      < 0xa007000 0x69 >;            /* in zephyr\dts\arm\microchip\pic32c\pic32ck_sg_gc\common\pic32ck_sg_gc.dtsi:391 */
			reg-names = "adc",
			            "fuses";                 /* in zephyr\dts\arm\microchip\pic32c\pic32ck_sg_gc\common\pic32ck_sg_gc.dtsi:392 */
			interrupts = < 0x84 0x0 >,
			             < 0x85 0x0 >;           /* in zephyr\dts\arm\microchip\pic32c\pic32ck_sg_gc\common\pic32ck_sg_gc.dtsi:393 */
			interrupt-names = "global",
			                  "core0";           /* in zephyr\dts\arm\microchip\pic32c\pic32ck_sg_gc\common\pic32ck_sg_gc.dtsi:394 */
			num-channels = < 0xe >;              /* in zephyr\dts\arm\microchip\pic32c\pic32ck_sg_gc\common\pic32ck_sg_gc.dtsi:395 */
			#io-channel-cells = < 0x1 >;         /* in zephyr\dts\arm\microchip\pic32c\pic32ck_sg_gc\common\pic32ck_sg_gc.dtsi:396 */
			clocks = < &mclkperiph 0x24323f35 >,
			         < &gclkperiph 0x1fffe12a >; /* in zephyr\dts\arm\microchip\pic32c\pic32ck_sg_gc\common\pic32ck_sg_gc.dtsi:397 */
			clock-names = "mclk",
			              "gclk";                /* in zephyr\dts\arm\microchip\pic32c\pic32ck_sg_gc\common\pic32ck_sg_gc.dtsi:399 */
			status = "disabled";                 /* in zephyr\dts\arm\microchip\pic32c\pic32ck_sg_gc\common\pic32ck_sg_gc.dtsi:400 */
		};

		/* node '/soc/usb@4502a000' defined in zephyr\dts\arm\microchip\pic32c\pic32ck_sg_gc\common\pic32ck_sg_gc.dtsi:403 */
		usb0: zephyr_udc0: usb@4502a000 {
			compatible = "microchip,usb-g1";       /* in zephyr\dts\arm\microchip\pic32c\pic32ck_sg_gc\common\pic32ck_sg_gc.dtsi:404 */
			reg = < 0x4502a000 0x1fff >;           /* in zephyr\dts\arm\microchip\pic32c\pic32ck_sg_gc\common\pic32ck_sg_gc.dtsi:405 */
			interrupts = < 0x96 0x0 >,
			             < 0x97 0x0 >,
			             < 0x98 0x0 >,
			             < 0x99 0x0 >;             /* in zephyr\dts\arm\microchip\pic32c\pic32ck_sg_gc\common\pic32ck_sg_gc.dtsi:406 */
			interrupt-names = "usb",
			                  "sof",
			                  "trcpt0",
			                  "trcpt1";            /* in zephyr\dts\arm\microchip\pic32c\pic32ck_sg_gc\common\pic32ck_sg_gc.dtsi:407 */
			num-bidir-endpoints = < 0x8 >;         /* in zephyr\dts\arm\microchip\pic32c\pic32ck_sg_gc\common\pic32ck_sg_gc.dtsi:408 */
			maximum-speed = "full-speed";          /* in zephyr\dts\arm\microchip\pic32c\pic32ck_sg_gc\common\pic32ck_sg_gc.dtsi:409 */
			nvm-calib = < &cfm_calotp_usbfs >;     /* in zephyr\dts\arm\microchip\pic32c\pic32ck_sg_gc\common\pic32ck_sg_gc.dtsi:410 */
			calib-mapping = < 0x6 0x6 0x1f 0x5 >,
			                < 0x0 0x0 0x1f 0x29 >,
			                < 0xc 0xc 0x7 0x3 >;   /* in zephyr\dts\arm\microchip\pic32c\pic32ck_sg_gc\common\pic32ck_sg_gc.dtsi:411 */
			calib-mapping-names = "TRANSN",
			                      "TRANSP",
			                      "TRIM";          /* in zephyr\dts\arm\microchip\pic32c\pic32ck_sg_gc\common\pic32ck_sg_gc.dtsi:414 */
			clocks = < &mclkperiph 0x24347f3e >,
			         < &gclkperiph 0x1fffee37 >;   /* in zephyr\dts\arm\microchip\pic32c\pic32ck_sg_gc\common\pic32ck_sg_gc.dtsi:415 */
			clock-names = "mclk",
			              "gclk";                  /* in zephyr\dts\arm\microchip\pic32c\pic32ck_sg_gc\common\pic32ck_sg_gc.dtsi:417 */
			pinctrl-0 = < &usb_dc_default >;       /* in zephyr\boards\microchip\pic32c\pic32ck_sg01_cult\pic32ck_sg01_cult.dts:438 */
			pinctrl-names = "default";             /* in zephyr\boards\microchip\pic32c\pic32ck_sg01_cult\pic32ck_sg01_cult.dts:439 */
			status = "okay";                       /* in zephyr\boards\microchip\pic32c\pic32ck_sg01_cult\pic32ck_sg01_cult.dts:453 */
		};

		/* node '/soc/usb@46000000' defined in zephyr\dts\arm\microchip\pic32c\pic32ck_sg_gc\common\pic32ck_sg_gc.dtsi:421 */
		hsusb0: usb@46000000 {
			compatible = "microchip,usb-g2";     /* in zephyr\dts\arm\microchip\pic32c\pic32ck_sg_gc\common\pic32ck_sg_gc.dtsi:422 */
			reg = < 0x46000000 0x2000 >;         /* in zephyr\dts\arm\microchip\pic32c\pic32ck_sg_gc\common\pic32ck_sg_gc.dtsi:423 */
			interrupts = < 0x9a 0x0 >;           /* in zephyr\dts\arm\microchip\pic32c\pic32ck_sg_gc\common\pic32ck_sg_gc.dtsi:424 */
			clocks = < &mclkperiph 0x24053f0e >,
			         < &mclkperiph 0x24347f3e >,
			         < &gclkperiph 0x1fffee37 >; /* in zephyr\dts\arm\microchip\pic32c\pic32ck_sg_gc\common\pic32ck_sg_gc.dtsi:425 */
			clock-names = "ahb",
			              "apb",
			              "gclk";                /* in zephyr\dts\arm\microchip\pic32c\pic32ck_sg_gc\common\pic32ck_sg_gc.dtsi:428 */
			num-bidir-endpoints = < 0x8 >;       /* in zephyr\dts\arm\microchip\pic32c\pic32ck_sg_gc\common\pic32ck_sg_gc.dtsi:429 */
			num-in-endpoints = < 0x8 >;          /* in zephyr\dts\arm\microchip\pic32c\pic32ck_sg_gc\common\pic32ck_sg_gc.dtsi:430 */
			num-out-endpoints = < 0x8 >;         /* in zephyr\dts\arm\microchip\pic32c\pic32ck_sg_gc\common\pic32ck_sg_gc.dtsi:431 */
			maximum-speed = "high-speed";        /* in zephyr\dts\arm\microchip\pic32c\pic32ck_sg_gc\common\pic32ck_sg_gc.dtsi:432 */
			status = "disabled";                 /* in zephyr\boards\microchip\pic32c\pic32ck_sg01_cult\pic32ck_sg01_cult.dts:449 */
		};

		/* node '/soc/sdhc@45026000' defined in zephyr\dts\arm\microchip\pic32c\pic32ck_sg_gc\common\pic32ck_sg_gc.dtsi:436 */
		sdhc0: sdhc@45026000 {
			reg = < 0x45026000 0x234 >;          /* in zephyr\dts\arm\microchip\pic32c\pic32ck_sg_gc\common\pic32ck_sg_gc.dtsi:438 */
			interrupts = < 0x94 0x0 >;           /* in zephyr\dts\arm\microchip\pic32c\pic32ck_sg_gc\common\pic32ck_sg_gc.dtsi:439 */
			clocks = < &mclkperiph 0x24047f0b >,
			         < &gclkperiph 0x1fffec35 >,
			         < &gclkperiph 0x1fffd210 >; /* in zephyr\dts\arm\microchip\pic32c\pic32ck_sg_gc\common\pic32ck_sg_gc.dtsi:440 */
			clock-names = "mclk",
			              "gclk",
			              "gclk-slow";           /* in zephyr\dts\arm\microchip\pic32c\pic32ck_sg_gc\common\pic32ck_sg_gc.dtsi:443 */
			min-bus-freq = < 0x61a80 >;          /* in zephyr\dts\arm\microchip\pic32c\pic32ck_sg_gc\common\pic32ck_sg_gc.dtsi:444 */
			max-bus-freq = < 0x2faf080 >;        /* in zephyr\dts\arm\microchip\pic32c\pic32ck_sg_gc\common\pic32ck_sg_gc.dtsi:445 */
			compatible = "microchip,sdhc-g1";    /* in zephyr\boards\microchip\pic32c\pic32ck_sg01_cult\pic32ck_sg01_cult.dts:491 */
			pinctrl-0 = < &sdhc0_default >;      /* in zephyr\boards\microchip\pic32c\pic32ck_sg01_cult\pic32ck_sg01_cult.dts:492 */
			pinctrl-names = "default";           /* in zephyr\boards\microchip\pic32c\pic32ck_sg01_cult\pic32ck_sg01_cult.dts:493 */
			auto-cmd23;                          /* in zephyr\boards\microchip\pic32c\pic32ck_sg01_cult\pic32ck_sg01_cult.dts:494 */
			status = "okay";                     /* in zephyr\boards\microchip\pic32c\pic32ck_sg01_cult\pic32ck_sg01_cult.dts:495 */

			/* node '/soc/sdhc@45026000/disk' defined in zephyr\boards\microchip\pic32c\pic32ck_sg01_cult\pic32ck_sg01_cult.dts:497 */
			disk {
				compatible = "zephyr,sdmmc-disk"; /* in zephyr\boards\microchip\pic32c\pic32ck_sg01_cult\pic32ck_sg01_cult.dts:498 */
				disk-name = "SD";                 /* in zephyr\boards\microchip\pic32c\pic32ck_sg01_cult\pic32ck_sg01_cult.dts:499 */
				status = "okay";                  /* in zephyr\boards\microchip\pic32c\pic32ck_sg01_cult\pic32ck_sg01_cult.dts:500 */
			};
		};

		/* node '/soc/can@4501e000' defined in zephyr\dts\arm\microchip\pic32c\pic32ck_sg_gc\common\pic32ck_sg01_gc01_144.dtsi:11 */
		can0: can@4501e000 {
			compatible = "microchip,mcan-g1";                      /* in zephyr\dts\arm\microchip\pic32c\pic32ck_sg_gc\common\pic32ck_sg01_gc01_144.dtsi:12 */
			reg = < 0x4501e000 0x100 >;                            /* in zephyr\dts\arm\microchip\pic32c\pic32ck_sg_gc\common\pic32ck_sg01_gc01_144.dtsi:13 */
			interrupts = < 0x8f 0x0 >;                             /* in zephyr\dts\arm\microchip\pic32c\pic32ck_sg_gc\common\pic32ck_sg01_gc01_144.dtsi:14 */
			clocks = < &mclkperiph 0x24037f07 >,
			         < &gclkperiph 0x1fffe730 >;                   /* in zephyr\dts\arm\microchip\pic32c\pic32ck_sg_gc\common\pic32ck_sg01_gc01_144.dtsi:15 */
			clock-names = "mclk",
			              "gclk";                                  /* in zephyr\dts\arm\microchip\pic32c\pic32ck_sg_gc\common\pic32ck_sg01_gc01_144.dtsi:17 */
			bosch,mram-cfg = < 0x0 0x1c 0x8 0x3 0x3 0x0 0x3 0x3 >; /* in zephyr\dts\arm\microchip\pic32c\pic32ck_sg_gc\common\pic32ck_sg01_gc01_144.dtsi:18 */
			pinctrl-0 = < &can0_default >;                         /* in zephyr\boards\microchip\pic32c\pic32ck_sg01_cult\pic32ck_sg01_cult.dts:421 */
			pinctrl-names = "default";                             /* in zephyr\boards\microchip\pic32c\pic32ck_sg01_cult\pic32ck_sg01_cult.dts:422 */
			status = "okay";                                       /* in zephyr\boards\microchip\pic32c\pic32ck_sg01_cult\pic32ck_sg01_cult.dts:423 */
		};

		/* node '/soc/can@45020000' defined in zephyr\dts\arm\microchip\pic32c\pic32ck_sg_gc\common\pic32ck_sg01_gc01_144.dtsi:22 */
		can1: can@45020000 {
			compatible = "microchip,mcan-g1";                      /* in zephyr\dts\arm\microchip\pic32c\pic32ck_sg_gc\common\pic32ck_sg01_gc01_144.dtsi:23 */
			reg = < 0x45020000 0x100 >;                            /* in zephyr\dts\arm\microchip\pic32c\pic32ck_sg_gc\common\pic32ck_sg01_gc01_144.dtsi:24 */
			interrupts = < 0x90 0x0 >;                             /* in zephyr\dts\arm\microchip\pic32c\pic32ck_sg_gc\common\pic32ck_sg01_gc01_144.dtsi:25 */
			clocks = < &mclkperiph 0x2403bf08 >,
			         < &gclkperiph 0x1fffe831 >;                   /* in zephyr\dts\arm\microchip\pic32c\pic32ck_sg_gc\common\pic32ck_sg01_gc01_144.dtsi:26 */
			clock-names = "mclk",
			              "gclk";                                  /* in zephyr\dts\arm\microchip\pic32c\pic32ck_sg_gc\common\pic32ck_sg01_gc01_144.dtsi:28 */
			bosch,mram-cfg = < 0x0 0x1c 0x8 0x3 0x3 0x0 0x3 0x3 >; /* in zephyr\dts\arm\microchip\pic32c\pic32ck_sg_gc\common\pic32ck_sg01_gc01_144.dtsi:29 */
			status = "disabled";                                   /* in zephyr\dts\arm\microchip\pic32c\pic32ck_sg_gc\common\pic32ck_sg01_gc01_144.dtsi:30 */
		};

		/* node '/soc/sercom@45004000' defined in zephyr\dts\arm\microchip\pic32c\pic32ck_sg_gc\common\pic32ck_2051_sg_gc.dtsi:26 */
		sercom6: sercom@45004000 {
			compatible = "microchip,sercom-g1";  /* in zephyr\dts\arm\microchip\pic32c\pic32ck_sg_gc\common\pic32ck_2051_sg_gc.dtsi:27 */
			reg = < 0x45004000 0x38 >;           /* in zephyr\dts\arm\microchip\pic32c\pic32ck_sg_gc\common\pic32ck_2051_sg_gc.dtsi:28 */
			interrupts = < 0x6c 0x0 >,
			             < 0x6d 0x0 >,
			             < 0x6e 0x0 >,
			             < 0x6f 0x0 >,
			             < 0x70 0x0 >,
			             < 0x71 0x0 >;           /* in zephyr\dts\arm\microchip\pic32c\pic32ck_sg_gc\common\pic32ck_2051_sg_gc.dtsi:29 */
			interrupt-names = "error",
			                  "dre",
			                  "txc",
			                  "rxc",
			                  "rxs",
			                  "ctsic";           /* in zephyr\dts\arm\microchip\pic32c\pic32ck_sg_gc\common\pic32ck_2051_sg_gc.dtsi:30 */
			clocks = < &mclkperiph 0x2430bf2f >,
			         < &gclkperiph 0x1fffdb24 >; /* in zephyr\dts\arm\microchip\pic32c\pic32ck_sg_gc\common\pic32ck_2051_sg_gc.dtsi:31 */
			clock-names = "mclk",
			              "gclk";                /* in zephyr\dts\arm\microchip\pic32c\pic32ck_sg_gc\common\pic32ck_2051_sg_gc.dtsi:33 */
			status = "disabled";                 /* in zephyr\dts\arm\microchip\pic32c\pic32ck_sg_gc\common\pic32ck_2051_sg_gc.dtsi:34 */
		};

		/* node '/soc/sercom@45008000' defined in zephyr\dts\arm\microchip\pic32c\pic32ck_sg_gc\common\pic32ck_2051_sg_gc.dtsi:37 */
		sercom7: sercom@45008000 {
			compatible = "microchip,sercom-g1";  /* in zephyr\dts\arm\microchip\pic32c\pic32ck_sg_gc\common\pic32ck_2051_sg_gc.dtsi:38 */
			reg = < 0x45008000 0x38 >;           /* in zephyr\dts\arm\microchip\pic32c\pic32ck_sg_gc\common\pic32ck_2051_sg_gc.dtsi:39 */
			interrupts = < 0x72 0x0 >,
			             < 0x73 0x0 >,
			             < 0x74 0x0 >,
			             < 0x75 0x0 >,
			             < 0x76 0x0 >,
			             < 0x77 0x0 >;           /* in zephyr\dts\arm\microchip\pic32c\pic32ck_sg_gc\common\pic32ck_2051_sg_gc.dtsi:40 */
			interrupt-names = "error",
			                  "dre",
			                  "txc",
			                  "rxc",
			                  "rxs",
			                  "ctsic";           /* in zephyr\dts\arm\microchip\pic32c\pic32ck_sg_gc\common\pic32ck_2051_sg_gc.dtsi:41 */
			clocks = < &mclkperiph 0x2430ff30 >,
			         < &gclkperiph 0x1fffdc25 >; /* in zephyr\dts\arm\microchip\pic32c\pic32ck_sg_gc\common\pic32ck_2051_sg_gc.dtsi:42 */
			clock-names = "mclk",
			              "gclk";                /* in zephyr\dts\arm\microchip\pic32c\pic32ck_sg_gc\common\pic32ck_2051_sg_gc.dtsi:44 */
			status = "disabled";                 /* in zephyr\dts\arm\microchip\pic32c\pic32ck_sg_gc\common\pic32ck_2051_sg_gc.dtsi:45 */
		};

		/* node '/soc/tcc@4500c000' defined in zephyr\dts\arm\microchip\pic32c\pic32ck_sg_gc\common\pic32ck_2051_sg_gc.dtsi:48 */
		tcc6: tcc@4500c000 {
			compatible = "microchip,tcc-g1";     /* in zephyr\dts\arm\microchip\pic32c\pic32ck_sg_gc\common\pic32ck_2051_sg_gc.dtsi:49 */
			reg = < 0x4500c000 0x88 >;           /* in zephyr\dts\arm\microchip\pic32c\pic32ck_sg_gc\common\pic32ck_2051_sg_gc.dtsi:50 */
			interrupts = < 0x7e 0x0 >,
			             < 0x7f 0x0 >,
			             < 0x80 0x0 >;           /* in zephyr\dts\arm\microchip\pic32c\pic32ck_sg_gc\common\pic32ck_2051_sg_gc.dtsi:51 */
			interrupt-names = "cnt",
			                  "mc0",
			                  "mc1";             /* in zephyr\dts\arm\microchip\pic32c\pic32ck_sg_gc\common\pic32ck_2051_sg_gc.dtsi:52 */
			clocks = < &mclkperiph 0x2431bf33 >,
			         < &gclkperiph 0x1fffdf28 >; /* in zephyr\dts\arm\microchip\pic32c\pic32ck_sg_gc\common\pic32ck_2051_sg_gc.dtsi:53 */
			clock-names = "mclk",
			              "gclk";                /* in zephyr\dts\arm\microchip\pic32c\pic32ck_sg_gc\common\pic32ck_2051_sg_gc.dtsi:55 */
			max-bit-width = < 0x10 >;            /* in zephyr\dts\arm\microchip\pic32c\pic32ck_sg_gc\common\pic32ck_2051_sg_gc.dtsi:56 */
			channels = < 0x2 >;                  /* in zephyr\dts\arm\microchip\pic32c\pic32ck_sg_gc\common\pic32ck_2051_sg_gc.dtsi:57 */
			status = "disabled";                 /* in zephyr\dts\arm\microchip\pic32c\pic32ck_sg_gc\common\pic32ck_2051_sg_gc.dtsi:58 */
		};

		/* node '/soc/tcc@4500e000' defined in zephyr\dts\arm\microchip\pic32c\pic32ck_sg_gc\common\pic32ck_2051_sg_gc.dtsi:61 */
		tcc7: tcc@4500e000 {
			compatible = "microchip,tcc-g1";     /* in zephyr\dts\arm\microchip\pic32c\pic32ck_sg_gc\common\pic32ck_2051_sg_gc.dtsi:62 */
			reg = < 0x4500e000 0x88 >;           /* in zephyr\dts\arm\microchip\pic32c\pic32ck_sg_gc\common\pic32ck_2051_sg_gc.dtsi:63 */
			interrupts = < 0x81 0x0 >,
			             < 0x82 0x0 >,
			             < 0x83 0x0 >;           /* in zephyr\dts\arm\microchip\pic32c\pic32ck_sg_gc\common\pic32ck_2051_sg_gc.dtsi:64 */
			interrupt-names = "cnt",
			                  "mc0",
			                  "mc1";             /* in zephyr\dts\arm\microchip\pic32c\pic32ck_sg_gc\common\pic32ck_2051_sg_gc.dtsi:65 */
			clocks = < &mclkperiph 0x2431ff34 >,
			         < &gclkperiph 0x1fffe029 >; /* in zephyr\dts\arm\microchip\pic32c\pic32ck_sg_gc\common\pic32ck_2051_sg_gc.dtsi:66 */
			clock-names = "mclk",
			              "gclk";                /* in zephyr\dts\arm\microchip\pic32c\pic32ck_sg_gc\common\pic32ck_2051_sg_gc.dtsi:68 */
			max-bit-width = < 0x10 >;            /* in zephyr\dts\arm\microchip\pic32c\pic32ck_sg_gc\common\pic32ck_2051_sg_gc.dtsi:69 */
			channels = < 0x2 >;                  /* in zephyr\dts\arm\microchip\pic32c\pic32ck_sg_gc\common\pic32ck_2051_sg_gc.dtsi:70 */
			status = "disabled";                 /* in zephyr\dts\arm\microchip\pic32c\pic32ck_sg_gc\common\pic32ck_2051_sg_gc.dtsi:71 */
		};

		/* node '/soc/sdhc@45028000' defined in zephyr\dts\arm\microchip\pic32c\pic32ck_sg_gc\common\pic32ck_2051_sg_gc.dtsi:74 */
		sdhc1: sdhc@45028000 {
			compatible = "microchip,sdhc-g1";    /* in zephyr\dts\arm\microchip\pic32c\pic32ck_sg_gc\common\pic32ck_2051_sg_gc.dtsi:75 */
			reg = < 0x45028000 0x234 >;          /* in zephyr\dts\arm\microchip\pic32c\pic32ck_sg_gc\common\pic32ck_2051_sg_gc.dtsi:76 */
			interrupts = < 0x95 0x0 >;           /* in zephyr\dts\arm\microchip\pic32c\pic32ck_sg_gc\common\pic32ck_2051_sg_gc.dtsi:77 */
			clocks = < &mclkperiph 0x2404bf0c >,
			         < &gclkperiph 0x1fffed36 >,
			         < &gclkperiph 0x1fffd211 >; /* in zephyr\dts\arm\microchip\pic32c\pic32ck_sg_gc\common\pic32ck_2051_sg_gc.dtsi:78 */
			clock-names = "mclk",
			              "gclk",
			              "gclk-slow";           /* in zephyr\dts\arm\microchip\pic32c\pic32ck_sg_gc\common\pic32ck_2051_sg_gc.dtsi:81 */
			min-bus-freq = < 0x61a80 >;          /* in zephyr\dts\arm\microchip\pic32c\pic32ck_sg_gc\common\pic32ck_2051_sg_gc.dtsi:82 */
			max-bus-freq = < 0x2faf080 >;        /* in zephyr\dts\arm\microchip\pic32c\pic32ck_sg_gc\common\pic32ck_2051_sg_gc.dtsi:83 */
			status = "disabled";                 /* in zephyr\dts\arm\microchip\pic32c\pic32ck_sg_gc\common\pic32ck_2051_sg_gc.dtsi:84 */
		};

		/* node '/soc/ethernet@45022000' defined in zephyr\dts\arm\microchip\pic32c\pic32ck_sg_gc\common\pic32ck_sg01_gc01.dtsi:13 */
		gmac: ethernet@45022000 {
			reg = < 0x45022000 0x400 >;           /* in zephyr\dts\arm\microchip\pic32c\pic32ck_sg_gc\common\pic32ck_sg01_gc01.dtsi:15 */
			interrupts = < 0x91 0x0 >;            /* in zephyr\dts\arm\microchip\pic32c\pic32ck_sg_gc\common\pic32ck_sg01_gc01.dtsi:16 */
			interrupt-names = "gmac";             /* in zephyr\dts\arm\microchip\pic32c\pic32ck_sg_gc\common\pic32ck_sg01_gc01.dtsi:17 */
			num-queues = < 0x1 >;                 /* in zephyr\dts\arm\microchip\pic32c\pic32ck_sg_gc\common\pic32ck_sg01_gc01.dtsi:18 */
			clocks = < &mclkperiph 0x2403ff09 >,
			         < &mclkperiph 0x2433ff3c >,
			         < &gclkperiph 0x1fffe932 >,
			         < &gclkperiph 0x1fffea33 >;  /* in zephyr\dts\arm\microchip\pic32c\pic32ck_sg_gc\common\pic32ck_sg01_gc01.dtsi:19 */
			clock-names = "mclk-ahb",
			              "mclk-apb",
			              "gclk-tx",
			              "gclk-tsu";             /* in zephyr\dts\arm\microchip\pic32c\pic32ck_sg_gc\common\pic32ck_sg01_gc01.dtsi:23 */
			compatible = "microchip,gmac-g1-eth"; /* in zephyr\boards\microchip\pic32c\pic32ck_sg01_cult\pic32ck_sg01_cult.dts:467 */
			pinctrl-0 = < &gmac_rmii >;           /* in zephyr\boards\microchip\pic32c\pic32ck_sg01_cult\pic32ck_sg01_cult.dts:468 */
			pinctrl-names = "default";            /* in zephyr\boards\microchip\pic32c\pic32ck_sg01_cult\pic32ck_sg01_cult.dts:469 */
			nvmem-cells = < &mac_address >;       /* in zephyr\boards\microchip\pic32c\pic32ck_sg01_cult\pic32ck_sg01_cult.dts:471 */
			nvmem-cell-names = "mac-address";     /* in zephyr\boards\microchip\pic32c\pic32ck_sg01_cult\pic32ck_sg01_cult.dts:472 */
			phy-handle = < &phy >;                /* in zephyr\boards\microchip\pic32c\pic32ck_sg01_cult\pic32ck_sg01_cult.dts:473 */
			status = "okay";                      /* in zephyr\boards\microchip\pic32c\pic32ck_sg01_cult\pic32ck_sg01_cult.dts:474 */

			/* node '/soc/ethernet@45022000/mdio' defined in zephyr\dts\arm\microchip\pic32c\pic32ck_sg_gc\common\pic32ck_sg01_gc01.dtsi:26 */
			mdio: mdio {
				#address-cells = < 0x1 >;              /* in zephyr\dts\arm\microchip\pic32c\pic32ck_sg_gc\common\pic32ck_sg01_gc01.dtsi:28 */
				#size-cells = < 0x0 >;                 /* in zephyr\dts\arm\microchip\pic32c\pic32ck_sg_gc\common\pic32ck_sg01_gc01.dtsi:29 */
				compatible = "microchip,gmac-g1-mdio"; /* in zephyr\boards\microchip\pic32c\pic32ck_sg01_cult\pic32ck_sg01_cult.dts:478 */
				pinctrl-0 = < &mdio_default >;         /* in zephyr\boards\microchip\pic32c\pic32ck_sg01_cult\pic32ck_sg01_cult.dts:479 */
				pinctrl-names = "default";             /* in zephyr\boards\microchip\pic32c\pic32ck_sg01_cult\pic32ck_sg01_cult.dts:480 */
				status = "okay";                       /* in zephyr\boards\microchip\pic32c\pic32ck_sg01_cult\pic32ck_sg01_cult.dts:481 */

				/* node '/soc/ethernet@45022000/mdio/ethernet-phy@0' defined in zephyr\boards\microchip\pic32c\pic32ck_sg01_cult\pic32ck_sg01_cult.dts:483 */
				phy: ethernet-phy@0 {
					compatible = "ethernet-phy"; /* in zephyr\boards\microchip\pic32c\pic32ck_sg01_cult\pic32ck_sg01_cult.dts:484 */
					status = "okay";             /* in zephyr\boards\microchip\pic32c\pic32ck_sg01_cult\pic32ck_sg01_cult.dts:485 */
					reg = < 0x0 >;               /* in zephyr\boards\microchip\pic32c\pic32ck_sg01_cult\pic32ck_sg01_cult.dts:486 */
					phandle = < 0xf >;           /* in zephyr\boards\microchip\pic32c\pic32ck_sg01_cult\pic32ck_sg01_cult.dts:473 */
				};
			};
		};
	};

	/* node '/cpus' defined in zephyr\dts\arm\microchip\pic32c\pic32ck_sg_gc\common\pic32ck_sg_gc.dtsi:16 */
	cpus {
		#address-cells = < 0x1 >; /* in zephyr\dts\arm\microchip\pic32c\pic32ck_sg_gc\common\pic32ck_sg_gc.dtsi:17 */
		#size-cells = < 0x0 >;    /* in zephyr\dts\arm\microchip\pic32c\pic32ck_sg_gc\common\pic32ck_sg_gc.dtsi:18 */

		/* node '/cpus/cpu@0' defined in zephyr\dts\arm\microchip\pic32c\pic32ck_sg_gc\common\pic32ck_sg_gc.dtsi:20 */
		cpu0: cpu@0 {
			device_type = "cpu";             /* in zephyr\dts\arm\microchip\pic32c\pic32ck_sg_gc\common\pic32ck_sg_gc.dtsi:21 */
			compatible = "arm,cortex-m33";   /* in zephyr\dts\arm\microchip\pic32c\pic32ck_sg_gc\common\pic32ck_sg_gc.dtsi:22 */
			reg = < 0x0 >;                   /* in zephyr\dts\arm\microchip\pic32c\pic32ck_sg_gc\common\pic32ck_sg_gc.dtsi:23 */
			#address-cells = < 0x1 >;        /* in zephyr\dts\arm\microchip\pic32c\pic32ck_sg_gc\common\pic32ck_sg_gc.dtsi:24 */
			#size-cells = < 0x1 >;           /* in zephyr\dts\arm\microchip\pic32c\pic32ck_sg_gc\common\pic32ck_sg_gc.dtsi:25 */
			clock-frequency = < 0x7270e00 >; /* in zephyr\boards\microchip\pic32c\pic32ck_sg01_cult\pic32ck_sg01_cult.dts:118 */

			/* node '/cpus/cpu@0/mpu@e000ed90' defined in zephyr\dts\arm\microchip\pic32c\pic32ck_sg_gc\common\pic32ck_sg_gc.dtsi:27 */
			mpu: mpu@e000ed90 {
				compatible = "arm,armv8m-mpu"; /* in zephyr\dts\arm\microchip\pic32c\pic32ck_sg_gc\common\pic32ck_sg_gc.dtsi:28 */
				reg = < 0xe000ed90 0x40 >;     /* in zephyr\dts\arm\microchip\pic32c\pic32ck_sg_gc\common\pic32ck_sg_gc.dtsi:29 */
			};
		};
	};

	/* node '/leds' defined in zephyr\boards\microchip\pic32c\pic32ck_sg01_cult\pic32ck_sg01_cult.dts:39 */
	leds {
		compatible = "gpio-leds"; /* in zephyr\boards\microchip\pic32c\pic32ck_sg01_cult\pic32ck_sg01_cult.dts:40 */

		/* node '/leds/led_0' defined in zephyr\boards\microchip\pic32c\pic32ck_sg01_cult\pic32ck_sg01_cult.dts:42 */
		led0: led_0 {
			gpios = < &portd_secure 0x14 0x1 >; /* in zephyr\boards\microchip\pic32c\pic32ck_sg01_cult\pic32ck_sg01_cult.dts:43 */
			label = "LED0";                     /* in zephyr\boards\microchip\pic32c\pic32ck_sg01_cult\pic32ck_sg01_cult.dts:44 */
		};

		/* node '/leds/led_1' defined in zephyr\boards\microchip\pic32c\pic32ck_sg01_cult\pic32ck_sg01_cult.dts:47 */
		led1: led_1 {
			gpios = < &portb_secure 0x19 0x1 >; /* in zephyr\boards\microchip\pic32c\pic32ck_sg01_cult\pic32ck_sg01_cult.dts:48 */
			label = "LED1";                     /* in zephyr\boards\microchip\pic32c\pic32ck_sg01_cult\pic32ck_sg01_cult.dts:49 */
		};
	};

	/* node '/buttons' defined in zephyr\boards\microchip\pic32c\pic32ck_sg01_cult\pic32ck_sg01_cult.dts:53 */
	buttons {
		compatible = "gpio-keys"; /* in zephyr\boards\microchip\pic32c\pic32ck_sg01_cult\pic32ck_sg01_cult.dts:54 */

		/* node '/buttons/button_0' defined in zephyr\boards\microchip\pic32c\pic32ck_sg01_cult\pic32ck_sg01_cult.dts:56 */
		button0: button_0 {
			gpios = < &portb_secure 0x1a 0x11 >; /* in zephyr\boards\microchip\pic32c\pic32ck_sg01_cult\pic32ck_sg01_cult.dts:57 */
			label = "SW0";                       /* in zephyr\boards\microchip\pic32c\pic32ck_sg01_cult\pic32ck_sg01_cult.dts:58 */
			zephyr,code = < 0xb >;               /* in zephyr\boards\microchip\pic32c\pic32ck_sg01_cult\pic32ck_sg01_cult.dts:59 */
		};

		/* node '/buttons/button_1' defined in zephyr\boards\microchip\pic32c\pic32ck_sg01_cult\pic32ck_sg01_cult.dts:62 */
		button1: button_1 {
			gpios = < &portd_secure 0x2 0x11 >; /* in zephyr\boards\microchip\pic32c\pic32ck_sg01_cult\pic32ck_sg01_cult.dts:63 */
			label = "SW1";                      /* in zephyr\boards\microchip\pic32c\pic32ck_sg01_cult\pic32ck_sg01_cult.dts:64 */
			zephyr,code = < 0x2 >;              /* in zephyr\boards\microchip\pic32c\pic32ck_sg01_cult\pic32ck_sg01_cult.dts:65 */
		};
	};

	/* node '/hid_dev_0' defined in zephyr\samples\subsys\usb\hid-mouse\app.overlay:8 */
	hid_dev_0: hid_dev_0 {
		compatible = "zephyr,hid-device"; /* in zephyr\samples\subsys\usb\hid-mouse\app.overlay:9 */
		label = "HID0";                   /* in zephyr\samples\subsys\usb\hid-mouse\app.overlay:10 */
		protocol-code = "none";           /* in zephyr\samples\subsys\usb\hid-mouse\app.overlay:11 */
		in-polling-period-us = < 0x3e8 >; /* in zephyr\samples\subsys\usb\hid-mouse\app.overlay:12 */
		in-report-size = < 0x40 >;        /* in zephyr\samples\subsys\usb\hid-mouse\app.overlay:13 */
	};
};
